VERSION ""

NS_ :

BS_:

BU_: DBW AKit Pacifica MPDM_Master MPDM_Requester HMI

BO_ 3221225472 VECTOR__INDEPENDENT_SIG_MSG: 0 Vector__XXX
 SG_ DBW_BrakeFault_Ch2 : 55|1@1+ (1,0) [0|1] "Bool" Vector__XXX
 SG_ DBW_BrakeFault_Ch1 : 54|1@1+ (1,0) [0|1] "Bool" Vector__XXX
 SG_ DBW_TransCurGear : 4|4@1+ (1,0) [0|15] "uint8" Vector__XXX

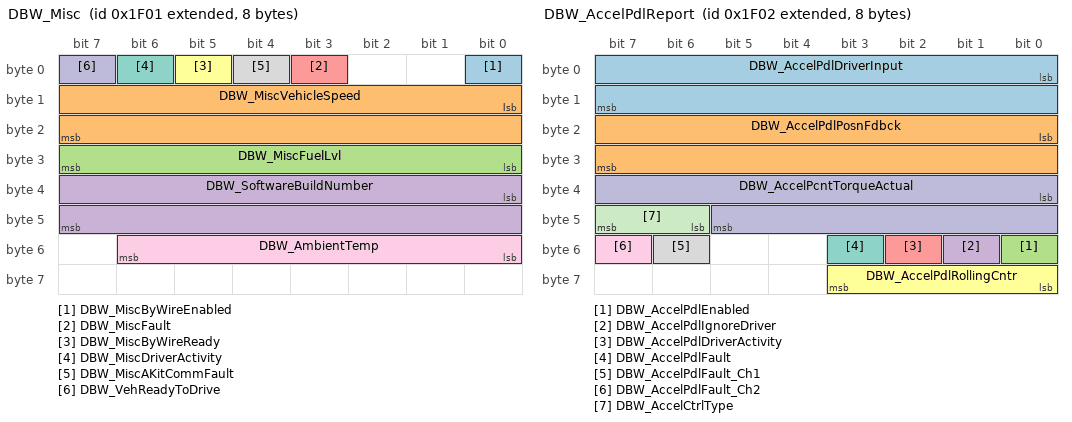
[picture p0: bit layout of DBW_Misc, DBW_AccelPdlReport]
BO_ 2147491585 DBW_Misc: 8 DBW
 SG_ DBW_MiscByWireEnabled : 0|1@1+ (1,0) [0|1] "Bool" Vector__XXX
 SG_ DBW_MiscVehicleSpeed : 8|16@1+ (0.00217014,0) [0|142.22] "m/s" Vector__XXX
 SG_ DBW_MiscFuelLvl : 24|8@1+ (0.5,0) [0|100] "%" Vector__XXX
 SG_ DBW_SoftwareBuildNumber : 32|16@1+ (1,0) [0|65535] "" Vector__XXX
 SG_ DBW_MiscFault : 3|1@1+ (1,0) [0|1] "Bool" Vector__XXX
 SG_ DBW_MiscByWireReady : 5|1@1+ (1,0) [0|1] "Bool" Vector__XXX
 SG_ DBW_MiscDriverActivity : 6|1@1+ (1,0) [0|1] "Bool" Vector__XXX
 SG_ DBW_MiscAKitCommFault : 4|1@1+ (1,0) [0|1] "Bool" Vector__XXX
 SG_ DBW_AmbientTemp : 48|7@1+ (1,-40) [-40|87] "C" Vector__XXX
 SG_ DBW_VehReadyToDrive : 7|1@1+ (1,0) [0|1] "Bool" Vector__XXX

BO_ 2147491586 DBW_AccelPdlReport: 8 DBW
 SG_ DBW_AccelPdlDriverInput : 0|16@1+ (0.1,0) [0|100] "%-pedal" Vector__XXX
 SG_ DBW_AccelPdlPosnFdbck : 16|16@1+ (0.1,0) [0|100] "%-pedal" Vector__XXX
 SG_ DBW_AccelPdlEnabled : 48|1@1+ (1,0) [0|1] "Bool" Vector__XXX
 SG_ DBW_AccelPdlIgnoreDriver : 49|1@1+ (1,0) [0|1] "Bool" Vector__XXX
 SG_ DBW_AccelPdlDriverActivity : 50|1@1+ (1,0) [0|1] "Bool" Vector__XXX
 SG_ DBW_AccelPdlRollingCntr : 56|4@1+ (1,0) [0|15] "" Vector__XXX
 SG_ DBW_AccelPdlFault : 51|1@1+ (1,0) [0|1] "Bool" Vector__XXX
 SG_ DBW_AccelPdlFault_Ch1 : 54|1@1+ (1,0) [0|1] "Bool" Vector__XXX
 SG_ DBW_AccelPdlFault_Ch2 : 55|1@1+ (1,0) [0|1] "Bool" Vector__XXX
 SG_ DBW_AccelPcntTorqueActual : 32|14@1+ (0.1,0) [0|100] "%-torque" Vector__XXX
 SG_ DBW_AccelCtrlType : 46|2@1+ (1,0) [0|3] "Enum" Vector__XXX

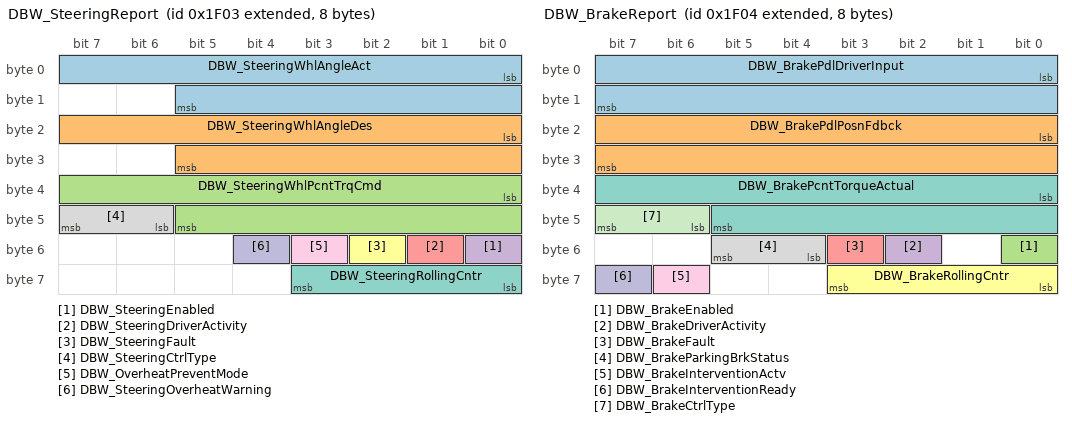
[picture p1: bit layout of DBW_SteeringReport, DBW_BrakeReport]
BO_ 2147491587 DBW_SteeringReport: 8 DBW
 SG_ DBW_SteeringWhlAngleAct : 0|14@1- (0.1,0) [-819.2|819.1] "deg" Vector__XXX
 SG_ DBW_SteeringWhlAngleDes : 16|14@1- (0.1,0) [-819.2|819.1] "deg" Vector__XXX
 SG_ DBW_SteeringWhlPcntTrqCmd : 32|14@1- (0.02,0) [-100|100] "%-torque" Vector__XXX
 SG_ DBW_SteeringEnabled : 48|1@1+ (1,0) [0|1] "Bool" Vector__XXX
 SG_ DBW_SteeringDriverActivity : 49|1@1+ (1,0) [0|1] "Bool" Vector__XXX
 SG_ DBW_SteeringFault : 50|1@1+ (1,0) [0|1] "Bool" Vector__XXX
 SG_ DBW_SteeringRollingCntr : 56|4@1+ (1,0) [0|15] "" Vector__XXX
 SG_ DBW_SteeringCtrlType : 46|2@1+ (1,0) [0|3] "Enum" Vector__XXX
 SG_ DBW_OverheatPreventMode : 51|1@1+ (1,0) [0|1] "Bool" Vector__XXX
 SG_ DBW_SteeringOverheatWarning : 52|1@1+ (1,0) [0|1] "Bool" Vector__XXX

BO_ 2147491588 DBW_BrakeReport: 8 DBW
 SG_ DBW_BrakePdlDriverInput : 0|16@1+ (0.1,0) [0|100] "%-pedal" Vector__XXX
 SG_ DBW_BrakePdlPosnFdbck : 16|16@1+ (0.1,0) [0|100] "%-pedal" Vector__XXX
 SG_ DBW_BrakeEnabled : 48|1@1+ (1,0) [0|1] "Bool" Vector__XXX
 SG_ DBW_BrakeDriverActivity : 50|1@1+ (1,0) [0|1] "Bool" Vector__XXX
 SG_ DBW_BrakeFault : 51|1@1+ (1,0) [0|1] "Bool" Vector__XXX
 SG_ DBW_BrakeRollingCntr : 56|4@1+ (1,0) [0|15] "" Vector__XXX
 SG_ DBW_BrakePcntTorqueActual : 32|14@1+ (0.1,0) [0|100] "%-torque" Vector__XXX
 SG_ DBW_BrakeParkingBrkStatus : 52|2@1+ (1,0) [0|3] "Enum" Vector__XXX
 SG_ DBW_BrakeInterventionActv : 62|1@1+ (1,0) [0|1] "Bool" Vector__XXX
 SG_ DBW_BrakeInterventionReady : 63|1@1+ (1,0) [0|1] "Bool" Vector__XXX
 SG_ DBW_BrakeCtrlType : 46|2@1+ (1,0) [0|3] "Enum" Vector__XXX

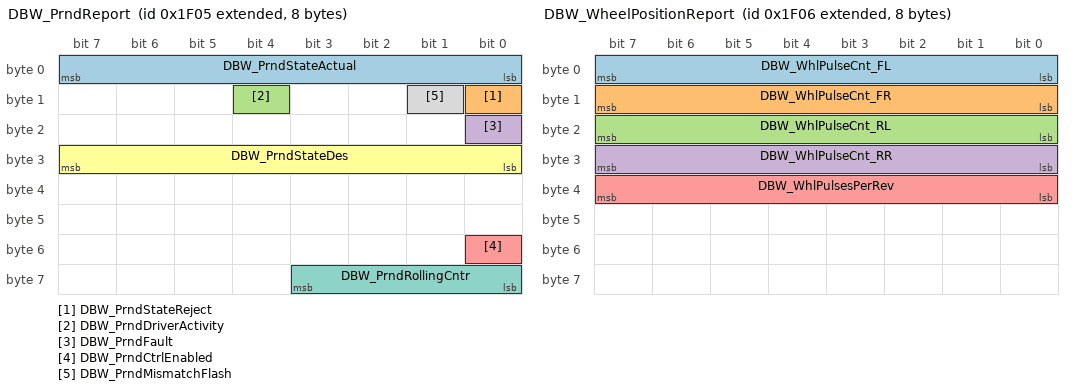
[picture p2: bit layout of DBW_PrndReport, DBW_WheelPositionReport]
BO_ 2147491589 DBW_PrndReport: 8 DBW
 SG_ DBW_PrndStateActual : 0|8@1+ (1,0) [0|255] "Enum" Vector__XXX
 SG_ DBW_PrndStateReject : 8|1@1+ (1,0) [0|1] "Bool" Vector__XXX
 SG_ DBW_PrndDriverActivity : 12|1@1+ (1,0) [0|1] "Bool" Vector__XXX
 SG_ DBW_PrndFault : 16|1@1+ (1,0) [0|1] "Bool" Vector__XXX
 SG_ DBW_PrndCtrlEnabled : 48|1@1+ (1,0) [0|1] "Bool" Vector__XXX
 SG_ DBW_PrndStateDes : 24|8@1+ (1,0) [0|255] "Enum" Vector__XXX
 SG_ DBW_PrndRollingCntr : 56|4@1+ (1,0) [0|15] "" Vector__XXX
 SG_ DBW_PrndMismatchFlash : 9|1@1+ (1,0) [0|1] "Bool" Vector__XXX

BO_ 2147491590 DBW_WheelPositionReport: 8 DBW
 SG_ DBW_WhlPulseCnt_FL : 0|8@1+ (1,0) [0|254] "Count" Vector__XXX
 SG_ DBW_WhlPulseCnt_FR : 8|8@1+ (1,0) [0|254] "Count" Vector__XXX
 SG_ DBW_WhlPulseCnt_RL : 16|8@1+ (1,0) [0|254] "Count" Vector__XXX
 SG_ DBW_WhlPulseCnt_RR : 24|8@1+ (1,0) [0|254] "Count" Vector__XXX
 SG_ DBW_WhlPulsesPerRev : 32|8@1+ (1,0) [0|255] "Count" Vector__XXX

BO_ 2147495682 AKit_AccelPdlRequest: 8 AKit
 SG_ AKit_AccelPdlReq m0 : 0|14@1+ (0.1,0) [0|100] "%-pedal" Vector__XXX
 SG_ AKit_AccelPdlEnblReq : 52|1@1+ (1,0) [0|1] "Bool" Vector__XXX
 SG_ AKit_AccelPdlIgnoreDriverOvrd : 53|1@1+ (1,0) [0|1] "Bool" Vector__XXX
 SG_ AKit_AccelPdlRollingCntr : 48|4@1+ (1,0) [0|15] "" Vector__XXX
 SG_ AKit_AccelReqType M : 40|3@0+ (1,0) [0|7] "Enum" Vector__XXX
 SG_ AKit_AccelPcntTorqueReq m1 : 0|14@1+ (0.1,0) [0|100] "%-torque" Vector__XXX
 SG_ AKit_SpeedReq m2 : 0|14@1+ (0.005,0) [0|81.915] "m/s" Vector__XXX
 SG_ AKit_SpeedModeRoadSlope m2 : 32|8@1- (0.2,0) [-25.5|25.5] "degrees" Vector__XXX
 SG_ AKit_AccelPdlChecksum : 56|8@1+ (1,0) [0|255] "" Vector__XXX
 SG_ AKit_SpeedModeAccelLim m2 : 16|8@1+ (0.1,0) [0|25.5] "m/s^2" Vector__XXX
 SG_ AKit_SpeedModePosJerkLim m2 : 24|8@1+ (0.1,0) [0|25.5] "m/s^3" Vector__XXX

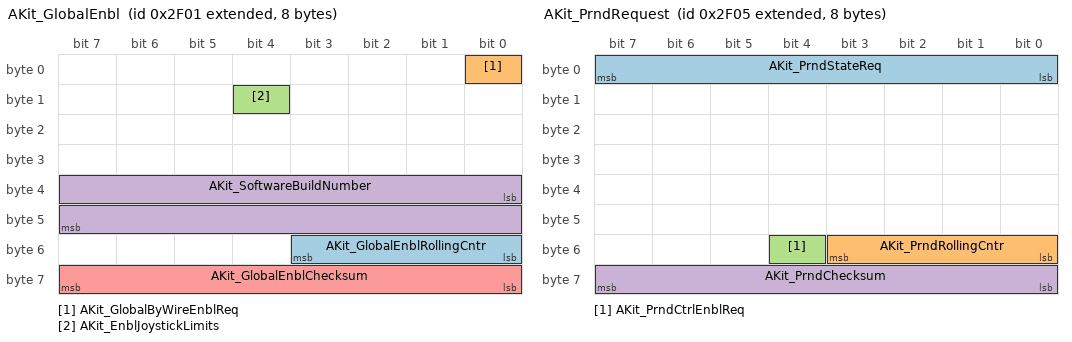
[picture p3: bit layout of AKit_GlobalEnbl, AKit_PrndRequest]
BO_ 2147495681 AKit_GlobalEnbl: 8 AKit
 SG_ AKit_GlobalEnblRollingCntr : 48|4@1+ (1,0) [0|15] "" Vector__XXX
 SG_ AKit_GlobalByWireEnblReq : 0|1@1+ (1,0) [0|1] "Bool" Vector__XXX
 SG_ AKit_EnblJoystickLimits : 12|1@1+ (1,0) [0|1] "Bool" Vector__XXX
 SG_ AKit_SoftwareBuildNumber : 32|16@1+ (1,0) [0|65535] "" Vector__XXX
 SG_ AKit_GlobalEnblChecksum : 56|8@1+ (1,0) [0|15] "" Vector__XXX

BO_ 2147495686 AKit_OtherActuators: 8 AKit
 SG_ AKit_TurnSignalReq : 4|2@1+ (1,0) [0|3] "Enum" Vector__XXX
 SG_ AKit_RightRearDoorReq : 8|2@1+ (1,0) [0|3] "Enum" Vector__XXX
 SG_ AKit_HighBeamReq : 28|2@1+ (1,0) [0|3] "" Vector__XXX
 SG_ AKit_FrontWiperReq : 16|4@1+ (1,0) [0|15] "Enum" Vector__XXX
 SG_ AKit_RearWiperReq : 20|4@1+ (1,0) [0|15] "Enum" Vector__XXX
 SG_ AKit_IgnitionReq : 24|3@1+ (1,0) [0|7] "Enum" Vector__XXX
 SG_ AKit_LeftRearDoorReq : 10|2@1+ (1,0) [0|3] "Enum" Vector__XXX
 SG_ AKit_LiftgateDoorReq : 32|2@1+ (1,0) [0|3] "Enum" Vector__XXX
 SG_ AKit_BlockBasicCruiseCtrlBtns : 13|1@1+ (1,0) [0|1] "" Vector__XXX
 SG_ AKit_BlockAdapCruiseCtrlBtns : 14|1@1+ (1,0) [0|1] "" Vector__XXX
 SG_ AKit_BlockTurnSigStalkInpts : 15|1@1+ (1,0) [0|1] "" Vector__XXX
 SG_ AKit_OtherRollingCntr : 48|4@1+ (1,0) [0|15] "" Vector__XXX
 SG_ AKit_OtherChecksum : 56|8@1+ (1,0) [0|255] "" Vector__XXX
 SG_ AKit_HornReq : 12|1@1+ (1,0) [0|1] "Bool" Vector__XXX
 SG_ AKit_LowBeamReq : 30|2@1+ (1,0) [0|2] "Enum" Vector__XXX
 SG_ AKit_DoorLockReq : 0|2@1+ (1,0) [0|2] "Enum" Vector__XXX
 SG_ AKit_RunningLightsReq : 34|3@1+ (1,0) [0|3] "Enum" Vector__XXX
 SG_ AKit_ModeLight_Red : 40|1@1+ (1,0) [0|1] "Bool" Vector__XXX
 SG_ AKit_ModeLight_Yellow : 41|1@1+ (1,0) [0|1] "Bool" Vector__XXX
 SG_ AKit_ModeLight_Green : 42|1@1+ (1,0) [0|1] "Bool" Vector__XXX
 SG_ AKit_ModeLight_Blue : 43|1@1+ (1,0) [0|1] "Bool" Vector__XXX
 SG_ AKit_DiffLock : 44|1@1+ (1,0) [0|1] "Bool" Vector__XXX
 SG_ AKit_OtherLightsReq : 46|2@1+ (1,0) [0|3] "Enum" Vector__XXX

BO_ 2147495683 AKit_SteeringRequest: 8 AKit
 SG_ AKit_SteeringWhlAngleReq m1 : 0|14@1- (0.1,0) [-819.2|819.1] "deg" Vector__XXX
 SG_ AKit_SteeringWhlAngleVelocityLim : 16|7@1+ (10,0) [0|1270] "deg/s" Vector__XXX
 SG_ AKit_SteerCtrlEnblReq : 52|1@1+ (1,0) [0|0] "" Vector__XXX
 SG_ AKit_SteerRollingCntr : 48|4@1+ (1,0) [0|15] "" Vector__XXX
 SG_ AKit_SteeringWhlIgnoreDriverOvrd : 53|1@1+ (1,0) [0|1] "" Vector__XXX
 SG_ AKit_SteeringWhlPcntTrqReq m0 : 0|14@1- (0.02,0) [-100|100] "%-torque" Vector__XXX
 SG_ AKit_SteeringReqType M : 40|3@0+ (1,0) [0|7] "Enum" Vector__XXX
 SG_ AKit_SteeringVehCurvatureReq m2 : 0|14@1- (0.0001,0) [-0.8192|0.8191] "1/m" Vector__XXX
 SG_ AKit_SteeringChecksum : 56|8@1+ (1,0) [0|255] "" Vector__XXX

BO_ 2147495684 AKit_BrakeRequest: 8 AKit
 SG_ AKit_BrakePedalReq m0 : 0|14@1+ (0.1,0) [0|100] "%-pedal" Vector__XXX
 SG_ AKit_BrakeRollingCntr : 48|4@1+ (1,0) [0|15] "" Vector__XXX
 SG_ AKit_BrakeCtrlEnblReq : 52|1@1+ (1,0) [0|1] "Bool" Vector__XXX
 SG_ AKit_BrakeCtrlReqType M : 40|3@0+ (1,0) [0|7] "Enum" Vector__XXX
 SG_ AKit_BrakePcntTorqueReq m1 : 0|14@1+ (0.1,0) [0|100] "%-torque" Vector__XXX
 SG_ AKit_SpeedModeDecelLim m2 : 16|8@1+ (0.1,0) [0|25.5] "m/s^2" Vector__XXX
 SG_ AKit_BrakeChecksum : 56|8@1+ (1,0) [0|255] "" Vector__XXX
 SG_ AKit_SpeedModeNegJerkLim m2 : 24|8@1+ (0.1,0) [0|25.5] "m/s^3" Vector__XXX
 SG_ AKit_ParkingBrkReq : 14|2@1+ (1,0) [0|2] "Enum" Vector__XXX

BO_ 2147495685 AKit_PrndRequest: 8 AKit
 SG_ AKit_PrndStateReq : 0|8@1+ (1,0) [0|255] "Enum" Vector__XXX
 SG_ AKit_PrndRollingCntr : 48|4@1+ (1,0) [0|15] "" Vector__XXX
 SG_ AKit_PrndCtrlEnblReq : 52|1@1+ (1,0) [0|1] "Bool" Vector__XXX
 SG_ AKit_PrndChecksum : 56|8@1+ (1,0) [0|255] "" Vector__XXX

BO_ 2147491599 DBW_DriverInputs: 8 DBW
 SG_ DBW_OccupAnyDoorOrHoodAjar : 0|1@1+ (1,0) [0|1] "Bool" Vector__XXX
 SG_ DBW_OccupAnyAirbagDeployed : 8|1@1+ (1,0) [0|1] "Bool" Vector__XXX
 SG_ DBW_OccupAnySeatbeltUnbuckled : 16|1@1+ (1,0) [0|1] "Bool" Vector__XXX
 SG_ DBW_DrvInptCruiseResumeBtn : 24|1@1+ (1,0) [0|1] "Bool" Vector__XXX
 SG_ DBW_DrvInptCruiseCancelBtn : 25|1@1+ (1,0) [0|1] "Bool" Vector__XXX
 SG_ DBW_DrvInptCruiseAccelBtn : 26|1@1+ (1,0) [0|1] "Bool" Vector__XXX
 SG_ DBW_DrvInptCruiseDecelBtn : 27|1@1+ (1,0) [0|1] "Bool" Vector__XXX
 SG_ DBW_DrvInptCruiseOnOffBtn : 28|1@1+ (1,0) [0|1] "Bool" Vector__XXX
 SG_ DBW_DrvInptAccOnOffBtn : 29|1@1+ (1,0) [0|1] "Bool" Vector__XXX
 SG_ DBW_DrvInptAccIncDistBtn : 30|1@1+ (1,0) [0|1] "Bool" Vector__XXX
 SG_ DBW_DrvInptAccDecDistBtn : 31|1@1+ (1,0) [0|1] "Bool" Vector__XXX
 SG_ DBW_DrvInptHiBeam : 32|2@1+ (1,0) [0|3] "enum" Vector__XXX
 SG_ DBW_DrvInptTurnSignal : 34|2@1+ (1,0) [0|3] "enum" Vector__XXX
 SG_ DBW_DrvInptWiper : 36|4@1+ (1,0) [0|15] "enum" Vector__XXX
 SG_ DBW_DrvInputStrWhlBtnA : 17|1@1+ (1,0) [0|0] "" Vector__XXX
 SG_ DBW_DrvInputStrWhlBtnB : 18|1@1+ (1,0) [0|0] "" Vector__XXX
 SG_ DBW_DrvInputStrWhlBtnC : 19|1@1+ (1,0) [0|0] "" Vector__XXX
 SG_ DBW_DrvInputStrWhlBtnD : 20|1@1+ (1,0) [0|0] "" Vector__XXX
 SG_ DBW_DrvInputStrWhlBtnE : 21|1@1+ (1,0) [0|0] "" Vector__XXX

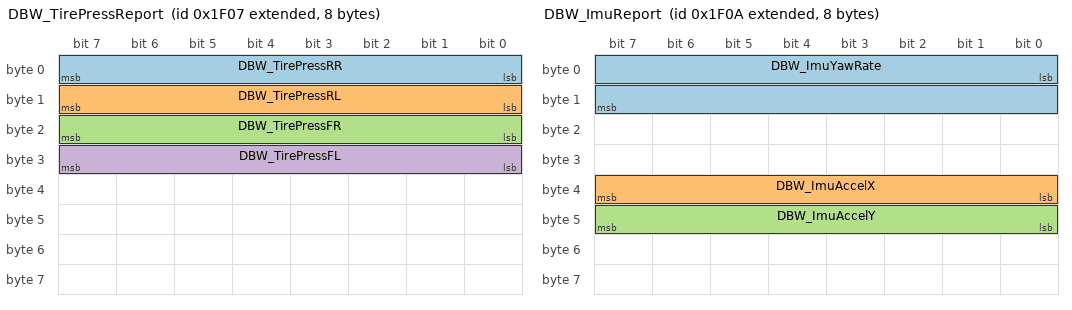
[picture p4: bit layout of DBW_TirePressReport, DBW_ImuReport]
BO_ 2147491591 DBW_TirePressReport: 8 DBW
 SG_ DBW_TirePressRR : 0|8@1+ (6.89476,0) [0|868.739] "kPa" Vector__XXX
 SG_ DBW_TirePressRL : 8|8@1+ (6.89476,0) [0|868.739] "kPa" Vector__XXX
 SG_ DBW_TirePressFR : 16|8@1+ (6.89476,0) [0|868.739] "kPa" Vector__XXX
 SG_ DBW_TirePressFL : 24|8@1+ (6.89476,0) [0|868.739] "kPa" Vector__XXX

BO_ 2147491592 DBW_VinReport: 8 DBW
 SG_ DBW_VinMultiplexor M : 0|2@1+ (1,0) [0|2] "" Vector__XXX
 SG_ DBW_VinDigit_01 m0 : 8|8@1+ (1,0) [30|90] "ascii" Vector__XXX
 SG_ DBW_VinDigit_02 m0 : 16|8@1+ (1,0) [30|90] "ascii" Vector__XXX
 SG_ DBW_VinDigit_03 m0 : 24|8@1+ (1,0) [30|90] "ascii" Vector__XXX
 SG_ DBW_VinDigit_04 m0 : 32|8@1+ (1,0) [30|90] "ascii" Vector__XXX
 SG_ DBW_VinDigit_05 m0 : 40|8@1+ (1,0) [30|90] "ascii" Vector__XXX
 SG_ DBW_VinDigit_06 m0 : 48|8@1+ (1,0) [30|90] "ascii" Vector__XXX
 SG_ DBW_VinDigit_07 m0 : 56|8@1+ (1,0) [30|90] "ascii" Vector__XXX
 SG_ DBW_VinDigit_08 m1 : 8|8@1+ (1,0) [30|90] "ascii" Vector__XXX
 SG_ DBW_VinDigit_09 m1 : 16|8@1+ (1,0) [30|90] "ascii" Vector__XXX
 SG_ DBW_VinDigit_10 m1 : 24|8@1+ (1,0) [30|90] "ascii" Vector__XXX
 SG_ DBW_VinDigit_11 m1 : 32|8@1+ (1,0) [30|90] "ascii" Vector__XXX
 SG_ DBW_VinDigit_12 m1 : 40|8@1+ (1,0) [30|90] "ascii" Vector__XXX
 SG_ DBW_VinDigit_13 m1 : 48|8@1+ (1,0) [30|90] "ascii" Vector__XXX
 SG_ DBW_VinDigit_14 m1 : 56|8@1+ (1,0) [30|90] "ascii" Vector__XXX
 SG_ DBW_VinDigit_15 m2 : 8|8@1+ (1,0) [30|90] "ascii" Vector__XXX
 SG_ DBW_VinDigit_16 m2 : 16|8@1+ (1,0) [30|90] "ascii" Vector__XXX
 SG_ DBW_VinDigit_17 m2 : 24|8@1+ (1,0) [30|90] "ascii" Vector__XXX

BO_ 2147491593 DBW_Reserved1: 8 DBW

BO_ 2147491594 DBW_ImuReport: 8 DBW
 SG_ DBW_ImuYawRate : 0|16@1+ (0.01,-327.68) [-327.68|327.66] "deg/sec" Vector__XXX
 SG_ DBW_ImuAccelX : 32|8@1+ (0.08,-10.24) [-10.24|10.08] "m/s/s" Vector__XXX
 SG_ DBW_ImuAccelY : 40|8@1+ (0.08,-10.24) [-10.24|10.08] "m/s/s" Vector__XXX

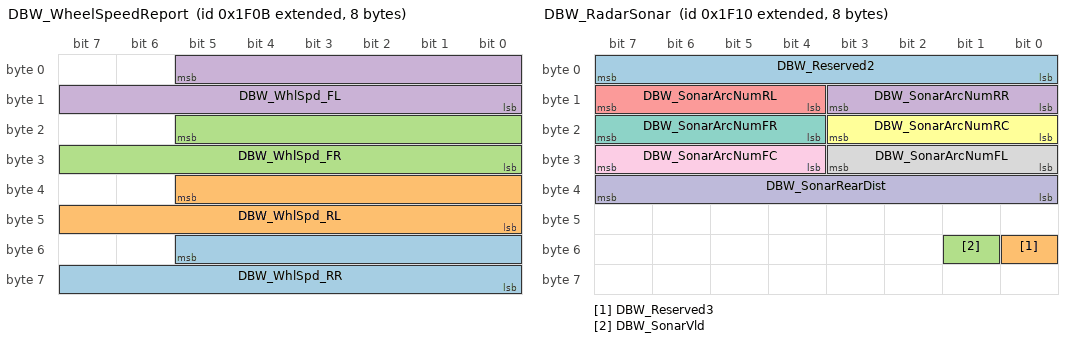
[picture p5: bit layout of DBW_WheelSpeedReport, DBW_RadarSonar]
BO_ 2147491595 DBW_WheelSpeedReport: 8 DBW
 SG_ DBW_WhlSpd_RR : 53|14@0- (0.0523599,0) [-428.932|428.827581] "rad/sec" Vector__XXX
 SG_ DBW_WhlSpd_RL : 37|14@0- (0.0523599,0) [-428.932|428.827581] "rad/sec" Vector__XXX
 SG_ DBW_WhlSpd_FR : 21|14@0- (0.0523599,0) [-428.932|428.827581] "rad/sec" Vector__XXX
 SG_ DBW_WhlSpd_FL : 5|14@0- (0.0523599,0) [-428.932|428.827581] "rad/sec" Vector__XXX

BO_ 2147491600 DBW_RadarSonar: 8 DBW
 SG_ DBW_Reserved2 : 0|8@1+ (1,0) [0|253] "m" Vector__XXX
 SG_ DBW_Reserved3 : 48|1@1+ (1,0) [0|1] "Bool" Vector__XXX
 SG_ DBW_SonarVld : 49|1@1+ (1,0) [0|1] "Bool" Vector__XXX
 SG_ DBW_SonarArcNumRR : 8|4@1+ (1,0) [0|15] "Enum" Vector__XXX
 SG_ DBW_SonarArcNumRL : 12|4@1+ (1,0) [0|15] "Enum" Vector__XXX
 SG_ DBW_SonarArcNumRC : 16|4@1+ (1,0) [0|15] "Enum" Vector__XXX
 SG_ DBW_SonarArcNumFR : 20|4@1+ (1,0) [0|15] "Enum" Vector__XXX
 SG_ DBW_SonarArcNumFL : 24|4@1+ (1,0) [0|15] "Enum" Vector__XXX
 SG_ DBW_SonarArcNumFC : 28|4@1+ (1,0) [0|15] "Enum" Vector__XXX
 SG_ DBW_SonarRearDist : 32|8@1+ (0.01,0) [0|2.54] "m" Vector__XXX

BO_ 1807 DBW_FaultText: 8 DBW
 SG_ FltTxt_PageNum M : 0|8@1+ (1,0) [0|255] "" Vector__XXX
 SG_ FltTxt_FaultId m0 : 15|16@0+ (1,0) [0|65535] "" Vector__XXX
 SG_ FltTxt_NumPages m0 : 40|8@1+ (1,0) [0|10] "" Vector__XXX
 SG_ FltTxt_FaultStatus m0 : 48|8@1+ (1,0) [0|2] "enum" Vector__XXX
 SG_ FltTxt_FaultSetRuntime m255 : 15|32@0+ (1,0) [0|0] "ms" Vector__XXX
 SG_ FltTxt_CRC m255 : 56|8@1+ (1,0) [0|255] "" Vector__XXX
 SG_ FltTxt_CurrentRuntime m254 : 39|32@0+ (1,0) [0|0] "ms" Vector__XXX
 SG_ FltTxt_Char01 m1 : 8|8@1+ (1,0) [0|255] "ascii" Vector__XXX
 SG_ FltTxt_Char02 m1 : 16|8@1+ (1,0) [0|255] "ascii" Vector__XXX
 SG_ FltTxt_Char03 m1 : 24|8@1+ (1,0) [0|255] "ascii" Vector__XXX
 SG_ FltTxt_Char04 m1 : 32|8@1+ (1,0) [0|255] "ascii" Vector__XXX
 SG_ FltTxt_Char05 m1 : 40|8@1+ (1,0) [0|255] "ascii" Vector__XXX
 SG_ FltTxt_Char06 m1 : 48|8@1+ (1,0) [0|255] "ascii" Vector__XXX
 SG_ FltTxt_Char07 m1 : 56|8@1+ (1,0) [0|255] "ascii" Vector__XXX
 SG_ FltTxt_Char08 m2 : 8|8@1+ (1,0) [0|255] "ascii" Vector__XXX
 SG_ FltTxt_Char09 m2 : 16|8@1+ (1,0) [0|255] "ascii" Vector__XXX
 SG_ FltTxt_Char10 m2 : 24|8@1+ (1,0) [0|255] "ascii" Vector__XXX
 SG_ FltTxt_Char11 m2 : 32|8@1+ (1,0) [0|255] "ascii" Vector__XXX
 SG_ FltTxt_Char12 m2 : 40|8@1+ (1,0) [0|255] "ascii" Vector__XXX
 SG_ FltTxt_Char13 m2 : 48|8@1+ (1,0) [0|255] "ascii" Vector__XXX
 SG_ FltTxt_Char14 m2 : 56|8@1+ (1,0) [0|255] "ascii" Vector__XXX
 SG_ FltTxt_Char15 m3 : 8|8@1+ (1,0) [0|255] "ascii" Vector__XXX
 SG_ FltTxt_Char16 m3 : 16|8@1+ (1,0) [0|255] "ascii" Vector__XXX
 SG_ FltTxt_Char17 m3 : 24|8@1+ (1,0) [0|255] "ascii" Vector__XXX
 SG_ FltTxt_Char18 m3 : 32|8@1+ (1,0) [0|255] "ascii" Vector__XXX
 SG_ FltTxt_Char19 m3 : 40|8@1+ (1,0) [0|255] "ascii" Vector__XXX
 SG_ FltTxt_Char20 m3 : 48|8@1+ (1,0) [0|255] "ascii" Vector__XXX
 SG_ FltTxt_Char21 m3 : 56|8@1+ (1,0) [0|255] "ascii" Vector__XXX
 SG_ FltTxt_Char22 m4 : 8|8@1+ (1,0) [0|255] "ascii" Vector__XXX
 SG_ FltTxt_Char23 m4 : 16|8@1+ (1,0) [0|255] "ascii" Vector__XXX
 SG_ FltTxt_Char24 m4 : 24|8@1+ (1,0) [0|255] "ascii" Vector__XXX
 SG_ FltTxt_Char25 m4 : 32|8@1+ (1,0) [0|255] "ascii" Vector__XXX
 SG_ FltTxt_Char26 m4 : 40|8@1+ (1,0) [0|255] "ascii" Vector__XXX
 SG_ FltTxt_Char27 m4 : 48|8@1+ (1,0) [0|255] "ascii" Vector__XXX
 SG_ FltTxt_Char28 m4 : 56|8@1+ (1,0) [0|255] "ascii" Vector__XXX
 SG_ FltTxt_Char29 m5 : 8|8@1+ (1,0) [0|255] "ascii" Vector__XXX
 SG_ FltTxt_Char30 m5 : 16|8@1+ (1,0) [0|255] "ascii" Vector__XXX
 SG_ FltTxt_Char31 m5 : 24|8@1+ (1,0) [0|255] "ascii" Vector__XXX
 SG_ FltTxt_Char32 m5 : 32|8@1+ (1,0) [0|255] "ascii" Vector__XXX
 SG_ FltTxt_Char33 m5 : 40|8@1+ (1,0) [0|255] "ascii" Vector__XXX
 SG_ FltTxt_Char34 m5 : 48|8@1+ (1,0) [0|255] "ascii" Vector__XXX
 SG_ FltTxt_Char35 m5 : 56|8@1+ (1,0) [0|255] "ascii" Vector__XXX
 SG_ FltTxt_Char36 m6 : 8|8@1+ (1,0) [0|255] "ascii" Vector__XXX
 SG_ FltTxt_Char37 m6 : 16|8@1+ (1,0) [0|255] "ascii" Vector__XXX
 SG_ FltTxt_Char38 m6 : 24|8@1+ (1,0) [0|255] "ascii" Vector__XXX
 SG_ FltTxt_Char39 m6 : 32|8@1+ (1,0) [0|255] "ascii" Vector__XXX
 SG_ FltTxt_Char40 m6 : 40|8@1+ (1,0) [0|255] "ascii" Vector__XXX
 SG_ FltTxt_Char41 m6 : 48|8@1+ (1,0) [0|255] "ascii" Vector__XXX
 SG_ FltTxt_Char42 m6 : 56|8@1+ (1,0) [0|255] "ascii" Vector__XXX
 SG_ FltTxt_Char43 m7 : 8|8@1+ (1,0) [0|255] "ascii" Vector__XXX
 SG_ FltTxt_Char44 m7 : 16|8@1+ (1,0) [0|255] "ascii" Vector__XXX
 SG_ FltTxt_Char45 m7 : 24|8@1+ (1,0) [0|255] "ascii" Vector__XXX
 SG_ FltTxt_Char46 m7 : 32|8@1+ (1,0) [0|255] "ascii" Vector__XXX
 SG_ FltTxt_Char47 m7 : 40|8@1+ (1,0) [0|255] "ascii" Vector__XXX
 SG_ FltTxt_Char48 m7 : 48|8@1+ (1,0) [0|255] "ascii" Vector__XXX
 SG_ FltTxt_Char49 m7 : 56|8@1+ (1,0) [0|255] "ascii" Vector__XXX

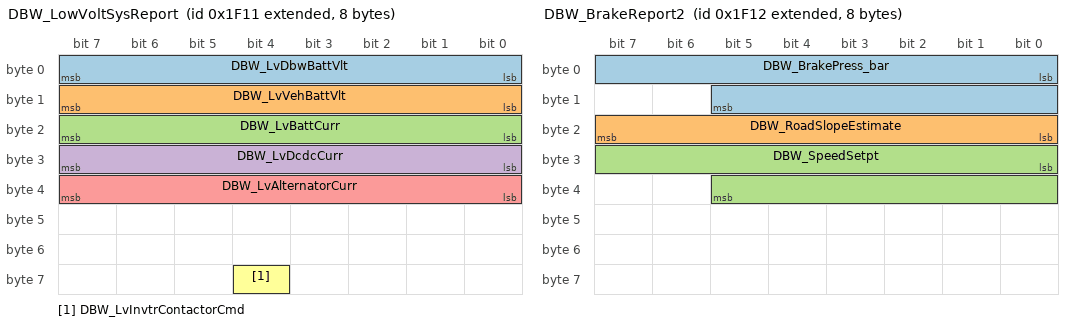
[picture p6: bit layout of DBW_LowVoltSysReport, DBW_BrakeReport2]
BO_ 2147491601 DBW_LowVoltSysReport: 8 DBW
 SG_ DBW_LvDbwBattVlt : 0|8@1+ (0.1,0) [0|25.5] "V" Vector__XXX
 SG_ DBW_LvVehBattVlt : 8|8@1+ (0.1,0) [0|25.5] "V" Vector__XXX
 SG_ DBW_LvBattCurr : 16|8@1+ (2,-256) [-256|254] "A" Vector__XXX
 SG_ DBW_LvDcdcCurr : 24|8@1+ (2,-256) [-256|254] "A" Vector__XXX
 SG_ DBW_LvAlternatorCurr : 32|8@1+ (2,-256) [-256|254] "A" Vector__XXX
 SG_ DBW_LvInvtrContactorCmd : 60|1@1+ (1,0) [0|1] "Bool" Vector__XXX

BO_ 2147491602 DBW_BrakeReport2: 8 DBW
 SG_ DBW_BrakePress_bar : 0|14@1+ (0.02,0) [0|200] "bar_gauge" Vector__XXX
 SG_ DBW_RoadSlopeEstimate : 16|8@1- (0.2,0) [-25.5|25.5] "degrees" Vector__XXX
 SG_ DBW_SpeedSetpt : 24|14@1+ (0.005,0) [0|81.915] "m/s" Vector__XXX

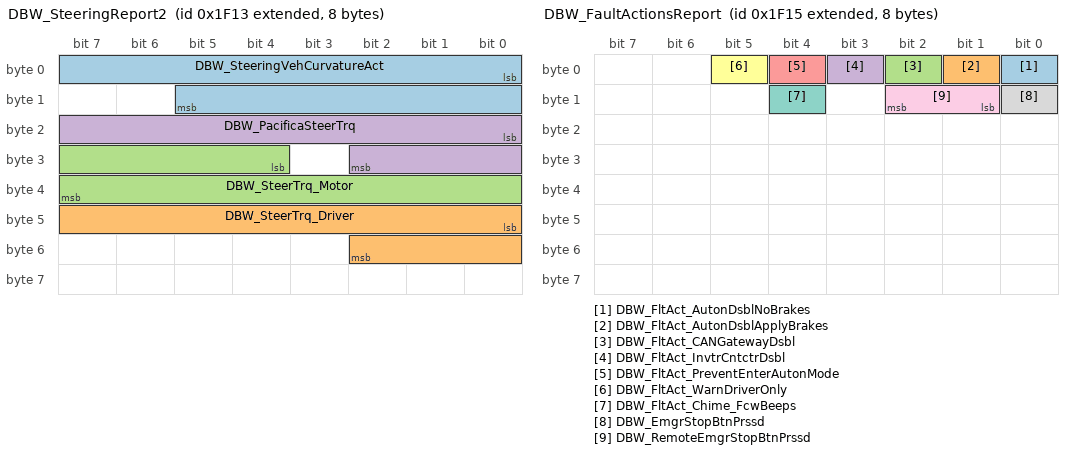
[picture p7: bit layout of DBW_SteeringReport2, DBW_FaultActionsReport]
BO_ 2147491603 DBW_SteeringReport2: 8 DBW
 SG_ DBW_SteeringVehCurvatureAct : 0|14@1- (0.0001,0) [-0.8192|0.8192] "1/m" Vector__XXX
 SG_ DBW_SteerTrq_Driver : 40|11@1- (0.1,0) [-100|100] "%-Torque" Vector__XXX
 SG_ DBW_SteerTrq_Motor : 28|12@1- (0.05,0) [-100|100] "%-Torque" Vector__XXX
 SG_ DBW_PacificaSteerTrq : 16|11@1+ (0.0078125,-8) [-8|7.99219] "Nm" Vector__XXX

BO_ 2147491604 DBW_OtherActuatorsReport: 8 DBW
 SG_ DBW_TurnSignalState : 4|3@1+ (1,0) [0|7] "Enum" Vector__XXX
 SG_ DBW_RightRearDoorState : 8|2@1+ (1,0) [0|3] "Enum" Vector__XXX
 SG_ DBW_HighBeamState : 28|2@1+ (1,0) [0|3] "Enum" Vector__XXX
 SG_ DBW_FrontWiperState : 16|4@1+ (1,0) [0|15] "Enum" Vector__XXX
 SG_ DBW_RearWiperState : 20|4@1+ (1,0) [0|15] "Enum" Vector__XXX
 SG_ DBW_IgnitionState : 24|3@1+ (1,0) [0|7] "Enum" Vector__XXX
 SG_ DBW_LeftRearDoorState : 10|2@1+ (1,0) [0|3] "Enum" Vector__XXX
 SG_ DBW_LiftgateDoorState : 32|2@1+ (1,0) [0|3] "Enum" Vector__XXX
 SG_ DBW_HornState : 12|2@1+ (1,0) [0|3] "Enum" Vector__XXX
 SG_ DBW_LowBeamState : 30|2@1+ (1,0) [0|3] "Enum" Vector__XXX
 SG_ DBW_OtherActRollingCntr : 56|4@1+ (1,0) [0|15] "" Vector__XXX
 SG_ DBW_DoorLockState : 0|2@1+ (1,0) [0|3] "Enum" Vector__XXX
 SG_ DBW_RunningLightsState : 34|2@1+ (1,0) [0|3] "Enum" Vector__XXX
 SG_ DBW_ModeLightState_Red : 40|2@1+ (1,0) [0|3] "Enum" Vector__XXX
 SG_ DBW_ModeLightState_Yellow : 42|2@1+ (1,0) [0|3] "Enum" Vector__XXX
 SG_ DBW_ModeLightState_Green : 48|2@1+ (1,0) [0|3] "Enum" Vector__XXX
 SG_ DBW_ModeLightState_Blue : 50|2@1+ (1,0) [0|3] "Enum" Vector__XXX
 SG_ DBW_DiffLockState : 44|2@1+ (1,0) [0|3] "Enum" Vector__XXX
 SG_ DBW_OtherLightsState : 46|2@1+ (1,0) [0|3] "Enum" Vector__XXX

BO_ 2147491605 DBW_FaultActionsReport: 8 DBW
 SG_ DBW_FltAct_AutonDsblNoBrakes : 0|1@1+ (1,0) [0|1] "" Vector__XXX
 SG_ DBW_FltAct_AutonDsblApplyBrakes : 1|1@1+ (1,0) [0|1] "" Vector__XXX
 SG_ DBW_FltAct_CANGatewayDsbl : 2|1@1+ (1,0) [0|1] "" Vector__XXX
 SG_ DBW_FltAct_InvtrCntctrDsbl : 3|1@1+ (1,0) [0|1] "" Vector__XXX
 SG_ DBW_FltAct_PreventEnterAutonMode : 4|1@1+ (1,0) [0|1] "" Vector__XXX
 SG_ DBW_FltAct_WarnDriverOnly : 5|1@1+ (1,0) [0|1] "" Vector__XXX
 SG_ DBW_FltAct_Chime_FcwBeeps : 12|1@1+ (1,0) [0|1] "" Vector__XXX
 SG_ DBW_EmgrStopBtnPrssd : 8|1@1+ (1,0) [0|1] "Bool" Vector__XXX
 SG_ DBW_RemoteEmgrStopBtnPrssd : 9|2@1+ (1,0) [0|3] "Enum" Vector__XXX

BO_ 2147491606 DBW_GpsReference: 8 DBW
 SG_ DBW_GpsRefLat : 0|16@1- (0.005,0) [-90|-90] "deg" Vector__XXX
 SG_ DBW_GpsRefLong : 16|16@1- (0.005,0) [-180|-180] "deg" Vector__XXX

BO_ 2147491607 DBW_GpsRemainder: 8 DBW
 SG_ DBW_GpsRemainderLat : 0|24@1- (0.001,0) [-8388.607|8388.608] "m" Vector__XXX
 SG_ DBW_GpsRemainderLong : 32|24@1- (0.001,0) [-8388.607|8388.61] "m" Vector__XXX

BO_ 2147495687 AKit_DumpBedRequest: 8 AKit
 SG_ AKit_DumpBedRollingCntr : 48|4@1+ (1,0) [0|15] "" Vector__XXX
 SG_ AKit_DumpBedChecksum : 56|8@1+ (1,0) [0|255] "" Vector__XXX
 SG_ AKit_DumpBedCtrlEnblReq : 52|1@1+ (1,0) [0|1] "" Vector__XXX
 SG_ AKit_DumpBedReqType M : 40|3@0+ (1,0) [0|1] "" Vector__XXX
 SG_ AKit_DumpBedModeReq m0 : 0|4@1+ (1,0) [0|5] "enum" Vector__XXX
 SG_ AKit_DumpBedLeverPercentReq m0 : 8|8@1+ (1,0) [0|100] "%" Vector__XXX
 SG_ AKit_DumpBedAnglReq m1 : 8|8@1+ (1,0) [0|100] "deg" Vector__XXX
 SG_ AKit_DumpBedIgnoreDriverOrvd : 53|1@1+ (1,0) [0|1] "" Vector__XXX
 SG_ AKit_DumpBedVelocityLimit : 16|8@1+ (0.5,0) [0|127.5] "deg/s" Vector__XXX

BO_ 2147495689 AKit_ArticulationRequest: 8 AKit
 SG_ AKit_ArticulationRollingCntr : 48|4@1+ (1,0) [0|15] "" Vector__XXX
 SG_ AKit_ArticulationChecksum : 56|8@1+ (1,0) [0|255] "" Vector__XXX
 SG_ AKit_ArticulationCtrlEnblReq : 52|1@1+ (1,0) [0|1] "" Vector__XXX
 SG_ AKit_ArticulationReqType M : 40|3@0+ (1,0) [0|1] "Enum" Vector__XXX
 SG_ AKit_ArticulationAngleReq m1 : 0|14@1- (0.1,0) [-90|90] "deg" Vector__XXX
 SG_ AKit_ArticulationIgnoreDrvrOvrd : 53|1@1+ (1,0) [0|1] "" Vector__XXX
 SG_ AKit_ArticulationVelocityLimit : 16|8@1+ (0.5,0) [0|127.5] "deg/s" Vector__XXX

BO_ 2147495688 AKit_EngineRequest: 8 AKit
 SG_ AKit_EngineCtrlEnblReq : 52|1@1+ (1,0) [0|1] "" Vector__XXX
 SG_ AKit_EngineRollingCntr : 48|4@1+ (1,0) [0|15] "" Vector__XXX
 SG_ AKit_EngineChecksum : 56|8@1+ (1,0) [0|255] "" Vector__XXX
 SG_ AKit_EngineModeReq m0 : 0|4@1+ (1,0) [0|4] "" Vector__XXX
 SG_ AKit_EngineReqType M : 40|3@0+ (1,0) [0|1] "" Vector__XXX

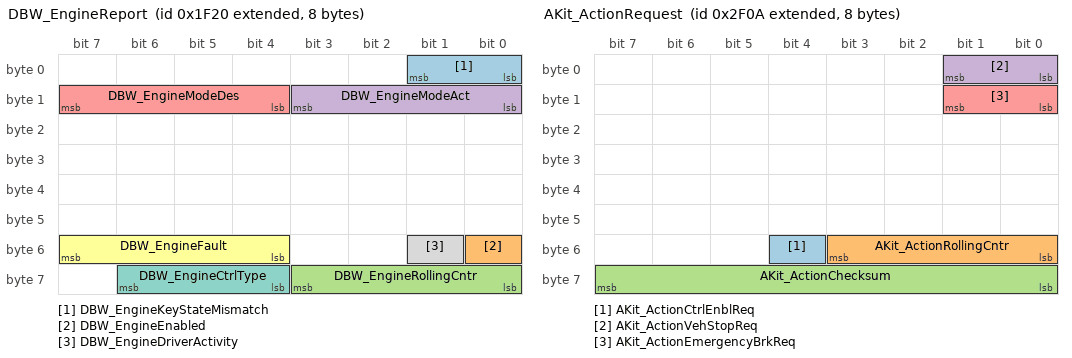
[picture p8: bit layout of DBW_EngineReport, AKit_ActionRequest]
BO_ 2147491616 DBW_EngineReport: 8 DBW
 SG_ DBW_EngineKeyStateMismatch : 0|2@1+ (1,0) [0|3] "enum" Vector__XXX
 SG_ DBW_EngineEnabled : 48|1@1+ (1,0) [0|1] "" Vector__XXX
 SG_ DBW_EngineRollingCntr : 56|4@1+ (1,0) [0|15] "" Vector__XXX
 SG_ DBW_EngineModeAct : 8|4@1+ (1,0) [0|4] "" Vector__XXX
 SG_ DBW_EngineModeDes : 12|4@1+ (1,0) [0|4] "" Vector__XXX
 SG_ DBW_EngineFault : 52|4@1+ (1,0) [0|15] "" Vector__XXX
 SG_ DBW_EngineCtrlType : 60|3@1+ (1,0) [0|1] "" Vector__XXX
 SG_ DBW_EngineDriverActivity : 49|1@1+ (1,0) [0|1] "" Vector__XXX

BO_ 2147495690 AKit_ActionRequest: 8 AKit
 SG_ AKit_ActionCtrlEnblReq : 52|1@1+ (1,0) [0|1] "" Vector__XXX
 SG_ AKit_ActionRollingCntr : 48|4@1+ (1,0) [0|15] "" Vector__XXX
 SG_ AKit_ActionChecksum : 56|8@1+ (1,0) [0|255] "" Vector__XXX
 SG_ AKit_ActionVehStopReq : 0|2@1+ (1,0) [0|3] "" Vector__XXX
 SG_ AKit_ActionEmergencyBrkReq : 8|2@1+ (1,0) [0|3] "" Vector__XXX

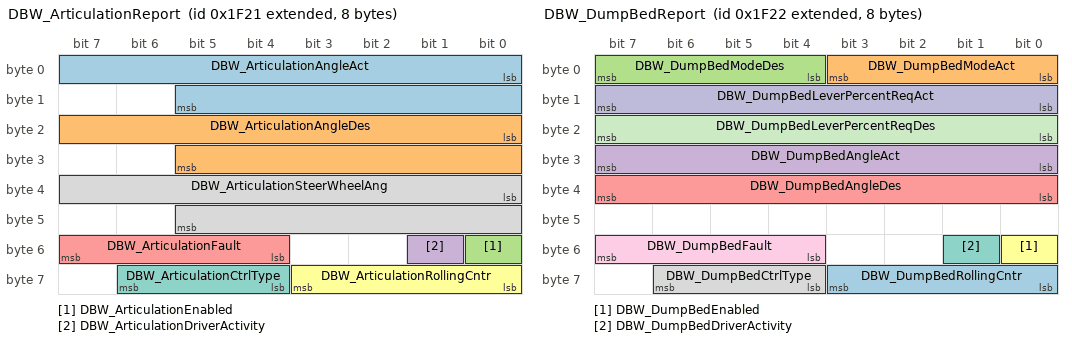
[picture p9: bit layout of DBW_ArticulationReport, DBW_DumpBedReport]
BO_ 2147491617 DBW_ArticulationReport: 8 DBW
 SG_ DBW_ArticulationAngleAct : 0|14@1- (0.1,0) [-90|90] "deg" Vector__XXX
 SG_ DBW_ArticulationAngleDes : 16|14@1- (0.1,0) [-90|90] "deg" Vector__XXX
 SG_ DBW_ArticulationEnabled : 48|1@1+ (1,0) [0|1] "" Vector__XXX
 SG_ DBW_ArticulationDriverActivity : 49|1@1+ (1,0) [0|1] "" Vector__XXX
 SG_ DBW_ArticulationFault : 52|4@1+ (1,0) [0|15] "" Vector__XXX
 SG_ DBW_ArticulationRollingCntr : 56|4@1+ (1,0) [0|15] "" Vector__XXX
 SG_ DBW_ArticulationCtrlType : 60|3@1+ (1,0) [0|1] "" Vector__XXX
 SG_ DBW_ArticulationSteerWheelAng : 32|14@1- (0.1,0) [-819.2|819.1] "deg" Vector__XXX

BO_ 2147491618 DBW_DumpBedReport: 8 DBW
 SG_ DBW_DumpBedRollingCntr : 56|4@1+ (1,0) [0|15] "" Vector__XXX
 SG_ DBW_DumpBedModeAct : 0|4@1+ (1,0) [0|5] "enum" Vector__XXX
 SG_ DBW_DumpBedModeDes : 4|4@1+ (1,0) [0|5] "enum" Vector__XXX
 SG_ DBW_DumpBedAngleAct : 24|8@1+ (1,0) [0|100] "deg" Vector__XXX
 SG_ DBW_DumpBedAngleDes : 32|8@1+ (1,0) [0|100] "deg" Vector__XXX
 SG_ DBW_DumpBedEnabled : 48|1@1+ (1,0) [0|1] "" Vector__XXX
 SG_ DBW_DumpBedDriverActivity : 49|1@1+ (1,0) [0|1] "" Vector__XXX
 SG_ DBW_DumpBedCtrlType : 60|3@1+ (1,0) [0|1] "" Vector__XXX
 SG_ DBW_DumpBedFault : 52|4@1+ (1,0) [0|1] "" Vector__XXX
 SG_ DBW_DumpBedLeverPercentReqAct : 8|8@1+ (1,0) [0|100] "%" Vector__XXX
 SG_ DBW_DumpBedLeverPercentReqDes : 16|8@1+ (1,0) [0|100] "%" Vector__XXX

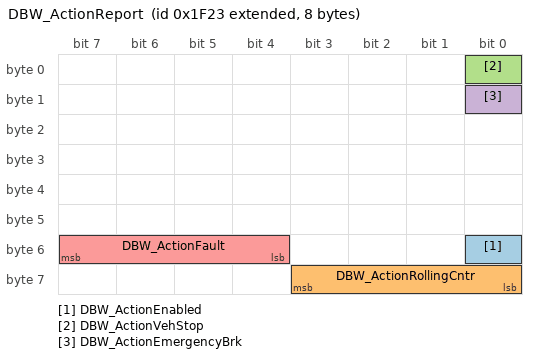
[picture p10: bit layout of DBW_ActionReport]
BO_ 2147491619 DBW_ActionReport: 8 DBW
 SG_ DBW_ActionEnabled : 48|1@1+ (1,0) [0|1] "" Vector__XXX
 SG_ DBW_ActionRollingCntr : 56|4@1+ (1,0) [0|15] "" Vector__XXX
 SG_ DBW_ActionVehStop : 0|1@1+ (1,0) [0|1] "" Vector__XXX
 SG_ DBW_ActionEmergencyBrk : 8|1@1+ (1,0) [0|1] "" Vector__XXX
 SG_ DBW_ActionFault : 52|4@1+ (1,0) [0|15] "" Vector__XXX

BO_ 2147491620 DBW_DumpBedReport2: 8 DBW
 SG_ DBW_Payload : 0|16@1+ (0.1,0) [0|6535.5] "metric ton" Vector__XXX
 SG_ DBW_DumpBed2RllngCntr : 56|4@1+ (1,0) [0|15] "" Vector__XXX

CM_ BU_ Pacifica "Just added a custom VIN-read message from this module";
CM_ BU_ MPDM_Master "Whichever module directly controls MPDM would be the MPDM Master (broadcasts status to other modules)";
CM_ BU_ MPDM_Requester "Any module that doesn't directly control the MPDM but might want to request a state would be an MPDM_Requester";
CM_ SG_ 3221225472 DBW_BrakeFault_Ch2 "VCU has detected hardware fault on brake sig 2


ROS Attribute: fault_ch2
";
CM_ SG_ 3221225472 DBW_BrakeFault_Ch1 "VCU has detected hardware fault on brake sig 1


ROS Attribute: fault_ch1
";
CM_ SG_ 3221225472 DBW_TransCurGear "Numeric gear number for step-gear (non hybrid) transmissions. This signal is just to allow the AKit to perform autostick (pseudo-manual) gear selection. 0 could be Park or Neutral. 1 could be Drive or Reverse. See DBW_PrndStateActual for P-R-N-D info.

For eCVT hybrids or single-speed EVs, this will only ever be 0 or 1.";
CM_ BO_ 2147491585 "ROS Topic: /raptor_dbw_interface/misc_report";
CM_ SG_ 2147491585 DBW_MiscByWireEnabled "Actual mode of the Drive-By-Wire system. THis is NOT read by the ROS system, it's only here so its in CAN logs for debugging purposes


ROS Attribute: drive_by_wire_enabled
";
CM_ SG_ 2147491585 DBW_MiscVehicleSpeed "scaled to match Pacifica's vehicle speed message


ROS Attribute: vehicle_speed
";
CM_ SG_ 2147491585 DBW_MiscFuelLvl "DBW will have to read IC_A1:AvgFuelLvl (liters) from the Pacifica and divide it by VehCfg3:VC_FUEL_CAP


ROS Attribute: fuel_level
";
CM_ SG_ 2147491585 DBW_SoftwareBuildNumber "Build number of the software that is currently flashed on the DBW control module


ROS Attribute: software_build_number
";
CM_ SG_ 2147491585 DBW_MiscFault "indicates one of the DBW actuators has faulted out. See individual report messages for more details.


ROS Attribute: general_actuator_fault
";
CM_ SG_ 2147491585 DBW_MiscByWireReady "Indicates the DBW is ready (vehicle running and not faulted) to enable if the AKit chooses to send an enable request. Driver overrides are not an input to this flag, so in some cases this flag will be true but by-wire control still might not be enabled.


ROS Attribute: by_wire_ready
";
CM_ SG_ 2147491585 DBW_MiscDriverActivity "Indicates the DBW has detected a driver overriding one of the actuators. This will disable by-wire operation until the enable request for the offending actuator is reset to zero. Note: Driver overrides will not clear the \"DBW_MiscByWireReady\" flag.


ROS Attribute: general_driver_activity
";
CM_ SG_ 2147491585 DBW_MiscAKitCommFault "Sets in conjunction with DBW_MiscFault IFF the DBW fault is related to losing communication with the autonomous system. This may have different fault actions than other faults in the DBW system.
Note: when this sets, the most often reason is because the AKit is not sending all 5 of the AKit* command messages. All 5 must be send, even if some of the enable requests are false.


ROS Attribute: comms_fault
";
CM_ SG_ 2147491585 DBW_AmbientTemp "Ambient (outside) temperature.

ROS Attribute:";
CM_ SG_ 2147491585 DBW_VehReadyToDrive "Indicates vehicle is ready to drive. For combustion-engine vehicles, it means the engine is started. For hybrids and electric vehicles, the engine may not be running but it means the driver has properly started the vehicle by pressing the ignition & brakes as needed.

This bit is NOT true if the vehicle is just in an ignition-on-engine-off state";
CM_ BO_ 2147491586 "ROS Topic: /raptor_dbw_interface/accelerator_pedal_report";
CM_ SG_ 2147491586 DBW_AccelPdlDriverInput "
ROS Attribute: pedal_input
";
CM_ SG_ 2147491586 DBW_AccelPdlPosnFdbck "Feedback from the Vehicle's Engine or Hybrid Control Module. 
For J1939 vehicles with TSC1 control (Volvo), this is a %-of-reference-torque.
For all other vehicles with physical pedal wiring intercepts (Pacifica), this is a %-of-pedal-position


ROS Attribute: pedal_output
";
CM_ SG_ 2147491586 DBW_AccelPdlEnabled "
ROS Attribute: enabled
";
CM_ SG_ 2147491586 DBW_AccelPdlIgnoreDriver "indicates the DBW system was requested by the AKit to ignore the driver's input.


ROS Attribute: ignore_driver
";
CM_ SG_ 2147491586 DBW_AccelPdlDriverActivity "Driver is pressing the accel pedal, which will switch the DBW system to manual mode unless the AKit is sending the AccelPdlIgnoreDriver flag. This flag latches and will unlatch when AKit_AccelPdlCtrlEnblCmd goes back to false.


ROS Attribute: driver_activity
";
CM_ SG_ 2147491586 DBW_AccelPdlRollingCntr "Watchdog alive rolling counter


ROS Attribute: rolling_counter
";
CM_ SG_ 2147491586 DBW_AccelPdlFault "AccelPdl system has a fault, either from the vehicle itself or from an error in the request message from the AKit


ROS Attribute: fault_accel_pedal_system
";
CM_ SG_ 2147491586 DBW_AccelPdlFault_Ch1 "VCU has detected hardware fault on accel pedal sig 1


ROS Attribute: fault_ch1
";
CM_ SG_ 2147491586 DBW_AccelPdlFault_Ch2 "VCU has detected hardware fault on accel pedal sig 2


ROS Attribute: fault_ch2
";
CM_ SG_ 2147491586 DBW_AccelPcntTorqueActual "This value is in % of a fixed reference value. This reference value depends only on the type of vehicle. Contact New Eagle to determine the reference value for your vehicle make/model.

100% reference values for each vehicle platform:
Chrylser Pacifica: 100% = 9.8 m/s^2 acceleration on flat ground at curb weight.
Volvo VNR:\t  100% = 9.8 m/s^2 acceleration on flat ground at curb weight.
Toyota Prius:\t  100% = 6.0 m/s^2 acceleration on flat ground at curb weight.

ROS Attribute: torque_actual
";
CM_ SG_ 2147491586 DBW_AccelCtrlType "Indicates whether the DBW kit is set to apply an open loop command (AKit responsible for performing all PID control),
 or requesting the DBW to apply PID control at the actuator level (turn wheel to a certain angle, or apply a certain amount of accel/brake torque & let AKit perform PID control on vehicle curvature/speed)
or requesting the DBW to perform all PID control at the vehicle level (control to a vehicle curvature and speed). If ReqType is 2, the requested speed will be taken from the signal AKit_SpeedReq in the AKit_AccelRequest message.
Some vehicles may not support all types!


ROS Attribute: control_type
";
CM_ BO_ 2147491587 "ROS Topic: /raptor_dbw_interface/steering_report";
CM_ SG_ 2147491587 DBW_SteeringWhlAngleAct "Actual position of the steering wheel. counterclockwise = positive


ROS Attribute: steering_wheel_angle
";
CM_ SG_ 2147491587 DBW_SteeringWhlAngleDes "Position that the DBW is trying to acheive. counterclockwise = positive


ROS Attribute: steering_wheel_angle_cmd
";
CM_ SG_ 2147491587 DBW_SteeringWhlPcntTrqCmd "Torque requested by the DBW to acheive the desired position. counterclockwise = positive

100% reference values for each vehicle platform:
Chrylser Pacifica: 100% = 105 Nm
Volvo VNR:\t  100% = 40 Nm
Toyota Prius:\t  not applicable, torque mode not supported

ROS Attribute: steering_wheel_torque
";
CM_ SG_ 2147491587 DBW_SteeringEnabled "
ROS Attribute: enabled
";
CM_ SG_ 2147491587 DBW_SteeringDriverActivity "Driver is turning the steering wheel, which will switch the DBW system to Manual mode. This flag latches and will unlatch when AKit_SteerCtrlEnblCmd goes back to false.


ROS Attribute: driver_activity
";
CM_ SG_ 2147491587 DBW_SteeringFault "Brake system has a fault, either from the vehicle itself or from an error in the request message from the AKit


ROS Attribute: fault_steering_system
";
CM_ SG_ 2147491587 DBW_SteeringRollingCntr "
ROS Attribute: rolling_counter
";
CM_ SG_ 2147491587 DBW_SteeringCtrlType "Indicates whether the DBW kit is set to apply an open loop command (AKit responsible for performing all PID control),
 or requesting the DBW to apply PID control at the actuator level (turn wheel to a certain angle, or apply a certain amount of accel/brake torque & let AKit perform PID control on vehicle curvature/speed)
or requesting the DBW to perform all PID control at the vehicle level (control to a vehicle curvature and speed). If ReqType is 2, the requested speed will be taken from the signal AKit_SpeedReq in the AKit_AccelRequest message.
Some vehicles may not support all types!


ROS Attribute: control_type
";
CM_ SG_ 2147491587 DBW_OverheatPreventMode "If the tires are rolling, the steady-state steering torque is relatively low compared to the not-moving case. If the vehicle speed is zero (tires arent rolling) then holding a constant steering angle requires the EPS motor to fight the spring force of the rubber on the pavement. In addition, the EPS system will have to apply this high torque continuously to prevent the steering wheel from springing back to the same angle as the rubber on the pavement. This high-torque for an extended period of time is not something the EPS system would encounter with a human driver because a human would release the steering wheel at 0mph. 

To better replicate the behavior of a human driver in this situation, if the vehicle speed is zero and the AKit steering request has not changed for more than 10 seconds then the DBW will set this flag to indicate that it has zeroed out the steering torque request (though autonomous control may still be enabled). As soon as the AKit steering request changes by a si";
CM_ SG_ 2147491587 DBW_SteeringOverheatWarning "This flag indicates the power steering motor is getting hot due to recent maneuvers commanded by the autonomous system (most likely lots of steering maneuvers at zero vehicle speed). Autonomous control and full steering torque will be allowed for some time, but eventually the power steering motor will derate itself. If this flag sets, the autonomous system needs to stop commanding the steering wheel to turn while at 0mph vehicle speed.";
CM_ BO_ 2147491588 "ROS Topic: /raptor_dbw_interface/Brake_report";
CM_ SG_ 2147491588 DBW_BrakePdlDriverInput "Position of actual driver requested brake pedal


ROS Attribute: pedal_position
";
CM_ SG_ 2147491588 DBW_BrakePdlPosnFdbck "Brake pedal command sent to vehicle


ROS Attribute: pedal_output
";
CM_ SG_ 2147491588 DBW_BrakeEnabled "Brake control enabled


ROS Attribute: enabled
";
CM_ SG_ 2147491588 DBW_BrakeDriverActivity "Driver is pressing the brakes, which will switch the DBW system to Manual mode. This flag latches and will unlatch when AKit_BrkPdlCtrlEnblCmd goes back to false.


ROS Attribute: driver_activity
";
CM_ SG_ 2147491588 DBW_BrakeFault "Brake system has a fault, either from the vehicle itself or from an error in the request message from the AKit


ROS Attribute: fault_brake_system
";
CM_ SG_ 2147491588 DBW_BrakeRollingCntr "Watchdog alive rolling counter


ROS Attribute: rolling_counter
";
CM_ SG_ 2147491588 DBW_BrakePcntTorqueActual "actual brake torque. This value is in % of a fixed reference value. This reference value depends only on the type of vehicle. Contact New Eagle to determine the reference value for your vehicle make/model.

100% reference values for each vehicle platform:
Chrylser Pacifica: 100% = 9.8 m/s^2 deceleration on flat ground at curb weight.
Volvo VNR:\t  100% = 9.8 m/s^2 deceleration on flat ground at curb weight.
Toyota Prius:\t  100% = 6.0 m/s^2 deceleration on flat ground at curb weight.

ROS Attribute: brake_torque_actual
";
CM_ SG_ 2147491588 DBW_BrakeParkingBrkStatus "
ROS Attribute: parking_brake
";
CM_ SG_ 2147491588 DBW_BrakeInterventionActv "indicates traction control or ABS on the OEM vehicle is active


ROS Attribute: intervention_active
";
CM_ SG_ 2147491588 DBW_BrakeInterventionReady "indicates traction control or ABS on the OEM vehicle is ready (not disabled but not currently active either)


ROS Attribute: intervention_ready
";
CM_ SG_ 2147491588 DBW_BrakeCtrlType "Indicates whether the DBW kit is set to apply an open loop command (AKit responsible for performing all PID control),
 or requesting the DBW to apply PID control at the actuator level (turn wheel to a certain angle, or apply a certain amount of accel/brake torque & let AKit perform PID control on vehicle curvature/speed)
or requesting the DBW to perform all PID control at the vehicle level (control to a vehicle curvature and speed). If ReqType is 2, the requested speed will be taken from the signal AKit_SpeedReq in the AKit_AccelRequest message.
Some vehicles may not support all types!


ROS Attribute: control_type
";
CM_ BO_ 2147491589 "ROS Topic: /raptor_dbw_interface/gear_report";
CM_ SG_ 2147491589 DBW_PrndStateActual "
ROS Attribute: state
";
CM_ SG_ 2147491589 DBW_PrndStateReject "may make this an enum later, after more testing


ROS Attribute: reject
";
CM_ SG_ 2147491589 DBW_PrndDriverActivity "indicates the driver is turning the PRND shift knob


ROS Attribute: driver_override
";
CM_ SG_ 2147491589 DBW_PrndFault "PRND select system has a fault, either from the vehicle itself or from an error in the request message from the AKit


ROS Attribute: gear_select_system_fault
";
CM_ SG_ 2147491589 DBW_PrndCtrlEnabled "PRND select system is under by-wire control. Typically matches the autonomous mode, except in some emergency stop lost-communication scenarios


ROS Attribute: enabled
";
CM_ BO_ 2147491590 "ROS Topic: /raptor_dbw_interface/wheel_position_report";
CM_ SG_ 2147491590 DBW_WhlPulseCnt_FL "Wheel pulse counter


ROS Attribute: front_left
";
CM_ SG_ 2147491590 DBW_WhlPulseCnt_FR "Wheel pulse counter


ROS Attribute: front_right
";
CM_ SG_ 2147491590 DBW_WhlPulseCnt_RL "Wheel pulse counter


ROS Attribute: rear_left
";
CM_ SG_ 2147491590 DBW_WhlPulseCnt_RR "Wheel pulse counter


ROS Attribute: rear_right
";
CM_ SG_ 2147491590 DBW_WhlPulsesPerRev "Number of wheel pulses in one revolution (96 for the Pacifica & Grand Cherokee)


ROS Attribute: wheel_pulses_per_rev
";
CM_ BO_ 2147495682 "Must be sent continuously, even if you're not planning to enable this actuator.

ROS Topic: /raptor_dbw_interface/accelerator_pedal_cmd";
CM_ SG_ 2147495682 AKit_AccelPdlReq "Used when AKit_AccelReqType = 0.
For J1939 vehicles with TSC1 control (Volvo), this is a %-of-reference-torque.
For all other vehicles with physical pedal wiring intercepts (Pacifica), this is a %-of-pedal-position


ROS Attribute: pedal_cmd
";
CM_ SG_ 2147495682 AKit_AccelPdlEnblReq "AKit_GlobalByWireEnblReq must also be true before the DBW system will look at this signal.


ROS Attribute: enable
";
CM_ SG_ 2147495682 AKit_AccelPdlIgnoreDriverOvrd "
ROS Attribute: ignore
";
CM_ SG_ 2147495682 AKit_AccelPdlRollingCntr "0-15 rolling counter


ROS Attribute: rolling_counter
";
CM_ SG_ 2147495682 AKit_AccelReqType "Indicates whether the AKit is requesting the DBW kit to apply an open loop command (AKit responsible for performing all PID control),
 or requesting the DBW to apply PID control at the actuator level (turn wheel to a certain angle, or apply a certain amount of accel/brake torque & let AKit perform PID control on vehicle curvature/speed)
or requesting the DBW to perform all PID control at the vehicle level (control to a vehicle curvature and speed)
Some vehicles may not support all types! Refer to the **CtrlType feedback from the DBW module to ensure your vehicle supports a given mode


ROS Attribute: control_type
";
CM_ SG_ 2147495682 AKit_AccelPcntTorqueReq "Used when AKit_AccelReqType = 1. This mode allows the AKit to request a constant torque value and let the DBW system adjust the pedal position to meet that torque. 

This value is in % of a fixed reference value. This reference value depends only on the type of vehicle.

Note that the reference value is the same in the braking and AccelPdl control logic. Because any given vehicle's braking system is usually more powerful than it's acceleration system (powertrain), the DBW system will typically reach the max pedal position when only roughly 50% accel torque is requested, again depending on the make/model of the vehicle.

100% reference values for each vehicle platform:
Chrylser Pacifica: \t100% = 9.8 m/s^2 acceleration on flat ground at curb weight.
Volvo VNR:\t  \t100% = 9.8 m/s^2 acceleration on flat ground at curb weight.
Toyota Prius:\t  \t100% = 6.0 m/s^2 acceleration on flat ground at curb weight.
Jeep Grand Cherokee:\t100% = 8.1 m/s^2 acceleration on flat ground at curb weight.

ROS A";
CM_ SG_ 2147495682 AKit_SpeedReq "Used when AKit_AccelReqType = 2 AND Kit_BrakeCtrllReqType = 2. Both must be 2 because speed control will use both the gas and brake (although a test engineer can leave one of those 2 actuators in manual mode by setting it's ***EnbReq flag to zero, just like in other ***ReqType modes).


ROS Attribute: speed_cmd
";
CM_ SG_ 2147495682 AKit_SpeedModeRoadSlope "positive = vehicle facing uphill. Used to adjust the torque requested to meet a given speed (steeper slope requires more torque to hold a constant speed). If this signal is not available, you can send a constant value of zero and speed control will still function but the speed controller will have greater error on sloped surfaces. If internally calibrated to do so, the DBW may also use its own estimate of road slope IFF the AKit is sending exactly 0 for this signal.

The steepest grades in the world are 21 degrees, so this scaling will encompass all real-world roads.

If vehicle is traveling downhill in reverse (facing uphill), this should still be a positive value. the DBW will compensate for PRND direction.


ROS Attribute: road_slope
";
CM_ SG_ 2147495682 AKit_AccelPdlChecksum "J1850 checksum (initial value 0xFF, polynomial 0x11D)";
CM_ SG_ 2147495682 AKit_SpeedModeAccelLim "0 = infinite (no limit). When AKit_AccelReqType = 2 (speed control), the DBW will limit acceleration to this value.
If vehicle is in reverse, this signal will still limit the accelerator pedal value (not the brake)


ROS Attribute: accel_limit
";
CM_ SG_ 2147495682 AKit_SpeedModePosJerkLim "0 = infinite (no limit). When AKit_AccelReqType = 2 (speed control), the DBW will limit jerk (rate-of-change of torque) to this value.
If vehicle is in reverse, this signal will still limit the accelerator pedal value (not the brake)


ROS Attribute: ";
CM_ BO_ 2147495681 "Must be sent continuously, even if you're not planning to enable this actuator.

ROS Topic: /raptor_dbw_interface/global_enable_cmd";
CM_ SG_ 2147495681 AKit_GlobalEnblRollingCntr "0-15 rolling counter


ROS Attribute: rolling_counter
";
CM_ SG_ 2147495681 AKit_GlobalByWireEnblReq "Global flag to allow by-wire DBW operation. The AKit must send this AND individual actuator enable flags to control any vehicle actuator. Also, if DBW_MiscByWireEnbl goes to zero for any reason uring autonomous driving (driver override, fault, ignition turned off, etc), then this signal must be cycled from 1 to 0 and back to 1 before reenabling autonomous mode. This is in order to acknoledge that the reason for the disable has been addressed and the driver or autonomous system truly wants to return to autonomous operation


ROS Attribute: global_enable
";
CM_ SG_ 2147495681 AKit_EnblJoystickLimits "For safety & drivability, if this bit is asserted, the DBW system will assume the vehicle is in joystick demonstration mode. This will limit vehicle speed, relinearize the input requests, rate limit, and clip the various actuators to allow smoother and safer operation while a human is demonstrating DBW operation with a joystick that has a high sensitivity. When a real autonomous system is controlling the DBW (more precise than a human), this bit should not be asserted so that the DBW won't apply rate limits, clips, and vehicle speed limits.


ROS Attribute: enable_joystick_limits
";
CM_ SG_ 2147495681 AKit_SoftwareBuildNumber "Build number of the software that is currently running on the AKit system.


ROS Attribute: ecu_build_number
";
CM_ SG_ 2147495681 AKit_GlobalEnblChecksum "J1850 checksum (initial value 0xFF, polynomial 0x11D)";
CM_ BO_ 2147495686 "Must be sent continuously, even if you're not planning to enable this actuator.

ROS Topic: /raptor_dbw_interface/misc_cmd";
CM_ SG_ 2147495686 AKit_TurnSignalReq "Currently supported by Prius only. Contact New Eagle if you are interested in adding support for Hazards on a Pacifica or Volvo vehicle.


ROS Attribute: cmd
";
CM_ SG_ 2147495686 AKit_RightRearDoorReq "Requested state of the given door, if electronically controlled. Currently supported by the Pacifica, but not the Volvo VNR Truck or Prius.


ROS Attribute: door_request_right_rear
";
CM_ SG_ 2147495686 AKit_HighBeamReq "Request high beam headlights. Supported on Pacifica, Volvo, and Prius.


ROS Attribute: high_beam_cmd
";
CM_ SG_ 2147495686 AKit_FrontWiperReq "Some vehicles (Volvo) don't support 6 different intermittent speeds. Vovlo only supports 4 intermittent speeds.


ROS Attribute: front_wiper_cmd
";
CM_ SG_ 2147495686 AKit_RearWiperReq "Only if a rear wiper is equipped on the vehicle. Some vehicles may not support all speeds shown here.


ROS Attribute: rear_wiper_cmd
";
CM_ SG_ 2147495686 AKit_IgnitionReq "Currently supported by the Volvo base kit, and the Pacifica add-on option. Contact New Eagle if you are interested in adding support for Ignition on a Pacifica or Prius vehicle.

On both Volvo and Pacifica, the ignition can be controled from any autonomous mode because you typically can't get into automous mode until after ignition is on. Obviously, though, the DBW module must be awoken by some wake input other than the vehicle ignition before it can accept a command to go from Ignition Off to any other ignition state.

ROS Attribute: ignition_cmd
";
CM_ SG_ 2147495686 AKit_LeftRearDoorReq "Requested state of the given door, if electronically controlled. Currently supported by the Pacifica, but not the Volvo VNR Truck or Prius.


ROS Attribute: door_request_left_rear
";
CM_ SG_ 2147495686 AKit_LiftgateDoorReq "Requested state of the given door, if electronically controlled. Currently supported by the Pacifica, but not the Volvo VNR Truck or Prius.


ROS Attribute: door_request_lift_gate
";
CM_ SG_ 2147495686 AKit_BlockBasicCruiseCtrlBtns "Allows the AKit to tell the DBW to block the driver's buttons presses from passing through the DBW gateway and enabling the vehicle's features. This exists in case the AKit wants to use those inputs for it's own purposes without the vehicle's OEM cruise control system activating


ROS Attribute: block_standard_cruise_buttons
";
CM_ SG_ 2147495686 AKit_BlockAdapCruiseCtrlBtns "Allows the AKit to tell the DBW to block the driver's buttons presses from passing through the DBW gateway and enabling the vehicle's features. This exists in case the AKit wants to use those inputs for it's own purposes without the vehicle's OEM cruise control system activating


ROS Attribute: block_adaptive_cruise_buttons
";
CM_ SG_ 2147495686 AKit_BlockTurnSigStalkInpts "Allows the AKit to tell the DBW to block the driver's buttons presses from passing through the DBW gateway and enabling the vehicle's features. This exists in case the AKit wants to use those inputs for it's own purposes without the vehicle's OEM cruise control system activating


ROS Attribute: block_turn_signal_stalk
";
CM_ SG_ 2147495686 AKit_OtherRollingCntr "0-15 rolling counter


ROS Attribute: rolling_counter
";
CM_ SG_ 2147495686 AKit_OtherChecksum "J1850 checksum (initial value 0xFF, polynomial 0x11D)";
CM_ SG_ 2147495686 AKit_HornReq "Currently supported by Prius & Volvo only. Contact New Eagle if you are interested in adding support for Horn on a Pacifica vehicle.";
CM_ SG_ 2147495686 AKit_LowBeamReq "Currently supported by Prius & Volvo only. Contact New Eagle if you are interested in adding support for Low Beam control on a Pacifica (in addition to the automatic-low-beam feature on the OEM vehicle).

They will turn on if the running lights are requested to be on.";
CM_ SG_ 2147495686 AKit_DiffLock "Engage differential axle lock.";
CM_ SG_ 2147495686 AKit_OtherLightsReq "Used to actuate any other accesory lighting";
CM_ BO_ 2147495683 "Must be sent continuously, even if you're not planning to enable this actuator.

ROS Topic: /raptor_dbw_interface/steering_cmd";
CM_ SG_ 2147495683 AKit_SteeringWhlAngleReq "counterclockwise = positive. Not all vehicles support the full range of travel. The Pacifica supports +/- 540deg, the Volvo VNR supports +/-750deg, Prius +/-500deg, and the Grand Cherokee +/-560 deg. See the signal DBW_SteeringWhlAngleDes to see if the DBW system is clipping an out-of-range request for your vehicle.


ROS Attribute: angle_cmd
";
CM_ SG_ 2147495683 AKit_SteeringWhlAngleVelocityLim "0 = infinite rate limit. Used only when SteeringWhlReqType = 1 or 2.


ROS Attribute: angle_velocity
";
CM_ SG_ 2147495683 AKit_SteerCtrlEnblReq "AKit_GlobalByWireEnblReq must also be true before the DBW system will look at this signal.


ROS Attribute: enable
";
CM_ SG_ 2147495683 AKit_SteerRollingCntr "0-15 rolling counter


ROS Attribute: rolling_counter
";
CM_ SG_ 2147495683 AKit_SteeringWhlIgnoreDriverOvrd "
ROS Attribute: ignore
";
CM_ SG_ 2147495683 AKit_SteeringWhlPcntTrqReq "requested steering wheel torque as a percent of a fixed reference value. This reference value depends only on the type of vehicle. Contact New Eagle to determine the reference value for your vehicle make/model.

Used in lieu of AKit_SteeringWhlAnglReq if the AKit is going to handle the PID control to acheive a desired position.

100% reference values for each vehicle platform:
Chrylser Pacifica: 100% = 105 Nm
Volvo VNR:\t  100% = 40 Nm
Toyota Prius:\t  not applicable, torque mode not supported

ROS Attribute: torque_cmd
";
CM_ SG_ 2147495683 AKit_SteeringReqType "Indicates whether the AKit is requesting the DBW kit to apply an open loop command (AKit responsible for performing all PID control),
 or requesting the DBW to apply PID control at the actuator level (turn wheel to a certain angle, or apply a certain amount of accel/brake torque & let AKit perform PID control on vehicle curvature/speed)
or requesting the DBW to perform all PID control at the vehicle level (control to a vehicle curvature and speed)
Some vehicles may not support all types! Refer to the **CtrlType feedback from the DBW module to ensure your vehicle supports a given mode


ROS Attribute: control_type
";
CM_ SG_ 2147495683 AKit_SteeringVehCurvatureReq "Used when AKit_SteeringWhlReqType = 2 (vehicle-level closed loop control). Curvature is the inverse of turn radius, such that 0 curvature = straight. Counterclockwise = positive


ROS Attribute: vehicle_curvature_cmd
";
CM_ SG_ 2147495683 AKit_SteeringChecksum "J1850 checksum (initial value 0xFF, polynomial 0x11D)";
CM_ BO_ 2147495684 "Must be sent continuously, even if you're not planning to enable this actuator.

ROS Topic: /raptor_dbw_interface/brake_cmd";
CM_ SG_ 2147495684 AKit_BrakePedalReq "Used when AKit_BrakeCtrlReqType = 0


ROS Attribute: pedal_cmd
";
CM_ SG_ 2147495684 AKit_BrakeRollingCntr "0-15 rolling counter


ROS Attribute: rolling_counter
";
CM_ SG_ 2147495684 AKit_BrakeCtrlEnblReq "AKit_GlobalByWireEnblReq must also be true before the DBW system will look at this signal.


ROS Attribute: enable
";
CM_ SG_ 2147495684 AKit_BrakeCtrlReqType "Indicates whether the AKit is requesting the DBW kit to apply an open loop command (AKit responsible for performing all PID control),
 or requesting the DBW to apply PID control at the actuator level (turn wheel to a certain angle, or apply a certain amount of accel/brake torque & let AKit perform PID control on vehicle curvature/speed)
or requesting the DBW to perform all PID control at the vehicle level (control to a vehicle curvature and speed). If ReqType is 2, the requested speed will be taken from the signal AKit_SpeedReq in the AKit_AccelRequest message.
Some vehicles may not support all types!


ROS Attribute: control_type
";
CM_ SG_ 2147495684 AKit_BrakePcntTorqueReq "Used when AKit_BrakeCtrlReqType = 1. This mode allows the AKit to request a constant torque value and let the DBW system adjust the pedal position to meet that torque. 

This value is in % of a fixed reference value. This reference value depends only on the type of vehicle. Contact New Eagle to determine the reference value for your vehicle make/model.

100% reference values for each vehicle platform:
Chrylser Pacifica: \t100% = 9.8 m/s^2 deceleration on flat ground at curb weight.
Volvo VNR:\t  \t100% = 9.8 m/s^2 deceleration on flat ground at curb weight.
Toyota Prius:\t\t100% = 6.0 m/s^2 deceleration on flat ground at curb weight.
Jeep Grand Cherokee:\t100% = 8.1 m/s^2 acceleration on flat ground at curb weight.

ROS Attribute: torque_cmd
";
CM_ SG_ 2147495684 AKit_SpeedModeDecelLim "0 = infinite (no limit). When AKit_AccelReqType = 2 (speed control), the DBW will limit decceleration to this value.
If vehicle is in reverse, this signal will still limit the brake pedal value (not the accelerator).
Overshoot & settling time requirements cannot be guaranteed with a limit above 7.5m/s^2. The no-limit value, or anything above 7.5m/s^2 should only be used for emergency braking.


ROS Attribute: decel_limit
";
CM_ SG_ 2147495684 AKit_BrakeChecksum "J1850 checksum (initial value 0xFF, polynomial 0x11D)";
CM_ SG_ 2147495684 AKit_SpeedModeNegJerkLim "0 = infinite (no limit). When AKit_BrakeCtrlReqType = 2 (speed control), the DBW will limit negative jerk (rate-of-change of torque) to this value.
If vehicle is in reverse, this signal will still limit the brake pedal value (not the accelerator).
Overshoot & settling time requirements cannot be guaranteed with a limit below X.Xm/s^2.


ROS Attribute:";
CM_ SG_ 2147495684 AKit_ParkingBrkReq "Currently support only as an add-on option to the Pacifica. Contact New Eagle if you are interested in adding this option to a different vehicle platform.

On the Pacifica, the parking brake can be applied in any ignition state and any autonomous state. the parking brake can be released in any autonomous state, but can NOT be released if the vehicle ignition is Off or Accessory. it must be in Run to release the parking brake.";
CM_ BO_ 2147495685 "Must be sent continuously, even if you're not planning to enable this actuator.

ROS Topic: /raptor_dbw_interface/gear_cmd ";
CM_ SG_ 2147495685 AKit_PrndStateReq "PRND shifter position request


ROS Attribute: cmd
";
CM_ SG_ 2147495685 AKit_PrndRollingCntr "0-15 rolling counter


ROS Attribute: rolling_counter
";
CM_ SG_ 2147495685 AKit_PrndCtrlEnblReq "AKit_GlobalByWireEnblReq must also be true before the DBW system will look at this signal.


ROS Attribute: enable
";
CM_ SG_ 2147495685 AKit_PrndChecksum "J1850 checksum (initial value 0xFF, polynomial 0x11D)";
CM_ BO_ 2147491599 "ROS Topic: /raptor_dbw_interface/driver_input_report";
CM_ SG_ 2147491599 DBW_OccupAnyDoorOrHoodAjar "
ROS Attribute: door_or_hood_ajar
";
CM_ SG_ 2147491599 DBW_OccupAnyAirbagDeployed "true if there has been a crash


ROS Attribute: airbag_deployed
";
CM_ SG_ 2147491599 DBW_OccupAnySeatbeltUnbuckled "indicates seatbelt warning lamp is on


ROS Attribute: any_seatbelt_unbuckled
";
CM_ SG_ 2147491599 DBW_DrvInptCruiseResumeBtn "0 = not pressed, 1 = pressed. Cruise buttons are used to enable autonomous driving if pressed in a special combination


ROS Attribute: cruise_resume_button
";
CM_ SG_ 2147491599 DBW_DrvInptCruiseCancelBtn "0 = not pressed, 1 = pressed. Cruise buttons are used to enable autonomous driving if pressed in a special combination


ROS Attribute: cruise_cancel_button
";
CM_ SG_ 2147491599 DBW_DrvInptCruiseAccelBtn "0 = not pressed, 1 = pressed. Cruise buttons are used to enable autonomous driving if pressed in a special combination


ROS Attribute: bool cruise_accel_button
";
CM_ SG_ 2147491599 DBW_DrvInptCruiseDecelBtn "0 = not pressed, 1 = pressed. Cruise buttons are used to enable autonomous driving if pressed in a special combination


ROS Attribute: cruise_decel_button
";
CM_ SG_ 2147491599 DBW_DrvInptCruiseOnOffBtn "0 = not pressed, 1 = pressed. Cruise buttons are used to enable autonomous driving if pressed in a special combination


ROS Attribute: cruise_on_off_button
";
CM_ SG_ 2147491599 DBW_DrvInptAccOnOffBtn "0 = not pressed, 1 = pressed. ACC = adaptive cruise


ROS Attribute: adaptive_cruise_on_off_button
";
CM_ SG_ 2147491599 DBW_DrvInptAccIncDistBtn "0 = not pressed, 1 = pressed. ACC = adaptive cruise


ROS Attribute: adaptive_cruise_increase_distance_button
";
CM_ SG_ 2147491599 DBW_DrvInptAccDecDistBtn "0 = not pressed, 1 = pressed. ACC = adaptive cruise


ROS Attribute: adaptive_cruise_decrease_distance_button
";
CM_ SG_ 2147491599 DBW_DrvInptHiBeam "
ROS Attribute: high_beam_headlights
";
CM_ SG_ 2147491599 DBW_DrvInptTurnSignal "
ROS Attribute: turn_signal
";
CM_ SG_ 2147491599 DBW_DrvInptWiper "
ROS Attribute: wiper
";
CM_ SG_ 2147491599 DBW_DrvInputStrWhlBtnA "0 = not pressed, 1 = pressed. This button varies across New Eagle vehicle platforms (Pacifica, Prius, Volvo, etc) because all steering wheels have different numbers and types of buttons available on the CAN bus. Contact New Eagle to find out which buttons are used on your platform, or press all the steering wheel buttons and see which of these signals respond.";
CM_ SG_ 2147491599 DBW_DrvInputStrWhlBtnB "0 = not pressed, 1 = pressed. This button varies across New Eagle vehicle platforms (Pacifica, Prius, Volvo, etc) because all steering wheels have different numbers and types of buttons available on the CAN bus. Contact New Eagle to find out which buttons are used on your platform, or press all the steering wheel buttons and see which of these signals respond.";
CM_ SG_ 2147491599 DBW_DrvInputStrWhlBtnC "0 = not pressed, 1 = pressed. This button varies across New Eagle vehicle platforms (Pacifica, Prius, Volvo, etc) because all steering wheels have different numbers and types of buttons available on the CAN bus. Contact New Eagle to find out which buttons are used on your platform, or press all the steering wheel buttons and see which of these signals respond.";
CM_ SG_ 2147491599 DBW_DrvInputStrWhlBtnD "0 = not pressed, 1 = pressed. This button varies across New Eagle vehicle platforms (Pacifica, Prius, Volvo, etc) because all steering wheels have different numbers and types of buttons available on the CAN bus. Contact New Eagle to find out which buttons are used on your platform, or press all the steering wheel buttons and see which of these signals respond.";
CM_ SG_ 2147491599 DBW_DrvInputStrWhlBtnE "0 = not pressed, 1 = pressed. This button varies across New Eagle vehicle platforms (Pacifica, Prius, Volvo, etc) because all steering wheels have different numbers and types of buttons available on the CAN bus. Contact New Eagle to find out which buttons are used on your platform, or press all the steering wheel buttons and see which of these signals respond.";
CM_ BO_ 2147491591 "ROS Topic: /raptor_dbw_interface/tire_pressure_report";
CM_ SG_ 2147491591 DBW_TirePressRR "pacifica scaling goes from 0 to 126, 1 psi per bit. convert to kpa for standard units here.


ROS Attribute: rear_right
";
CM_ SG_ 2147491591 DBW_TirePressRL "pacifica scaling goes from 0 to 126, 1 psi per bit. convert to kpa for standard units here.


ROS Attribute: rear_left
";
CM_ SG_ 2147491591 DBW_TirePressFR "pacifica scaling goes from 0 to 126, 1 psi per bit. convert to kpa for standard units here.


ROS Attribute: front_right
";
CM_ SG_ 2147491591 DBW_TirePressFL "pacifica scaling goes from 0 to 126, 1 psi per bit. convert to kpa for standard units here.


ROS Attribute: front_left
";
CM_ BO_ 2147491592 "ROS Topic: /raptor_dbw_interface/vin";
CM_ SG_ 2147491592 DBW_VinMultiplexor "message multiplexor";
CM_ BO_ 2147491593 "Message ID reserved for future additions

ROS Topic: N/A";
CM_ BO_ 2147491594 "IMU = Intertial Measurement Unit

ROS Topic: /raptor_dbw_interface/imu/data_raw";
CM_ SG_ 2147491594 DBW_ImuYawRate "postive = left.


ROS Attribute: angular_velocity.z
";
CM_ SG_ 2147491594 DBW_ImuAccelX "postive = forward.


ROS Attribute: linear_acceleration.x
";
CM_ SG_ 2147491594 DBW_ImuAccelY "positive = left.


ROS Attribute: linear_acceleration.y
";
CM_ BO_ 2147491595 "Some vehicles send an RPM, others a speed in km/h. Both are multiplexed into this message so that a common DBC can be maintained for New Eagle DBW vehicles

ROS Topic: /raptor_dbw_interface/wheel_speed_report";
CM_ SG_ 2147491595 DBW_WhlSpd_RR "positive is forward. Used on Pacifica.


ROS Attribute: rear_right
";
CM_ SG_ 2147491595 DBW_WhlSpd_RL "positive is forward. Used on Pacifica.


ROS Attribute: rear_left
";
CM_ SG_ 2147491595 DBW_WhlSpd_FR "positive is forward. Used on Pacifica.


ROS Attribute: front_right
";
CM_ SG_ 2147491595 DBW_WhlSpd_FL "positive is forward. Used on Pacifica.


ROS Attribute: front_left
";
CM_ BO_ 2147491600 "ROS Topic: /raptor_dbw_interface/surround_report";
CM_ SG_ 2147491600 DBW_Reserved2 "This signal is reserved for future addition of a gateway module to read the front ACC radar distance from the dedicated radar/camera CAN bus.


ROS Attribute: front_radar_object_distance
";
CM_ SG_ 2147491600 DBW_Reserved3 "This signal is reserved for a validity bit for the future addition of a gateway module to read the front ACC radar distance from the dedicated radar/camera CAN bus. This will be false when the Radar module is disabled or faulted.


ROS Attribute: front_radar_distance_valid
";
CM_ SG_ 2147491600 DBW_SonarVld "indicates if the values from the ultrasonic parking sensors are valid. This will be false when the Park Assist module is disabled or faulted.


ROS Attribute: parking_sonar_data_valid
";
CM_ SG_ 2147491600 DBW_SonarArcNumRR "
ROS Attribute: rear_right
";
CM_ SG_ 2147491600 DBW_SonarArcNumRL "
ROS Attribute: rear_left
";
CM_ SG_ 2147491600 DBW_SonarArcNumRC "
ROS Attribute: rear_center
";
CM_ SG_ 2147491600 DBW_SonarArcNumFR "
ROS Attribute: front_right
";
CM_ SG_ 2147491600 DBW_SonarArcNumFL "
ROS Attribute: front_left
";
CM_ SG_ 2147491600 DBW_SonarArcNumFC "
ROS Attribute: front_center
";
CM_ SG_ 2147491600 DBW_SonarRearDist "distance to nearest rear obstacle.


ROS Attribute: rear_radar_object_distance
";
CM_ BO_ 1807 "ASCII names of faults present in the DBW system

ROS Topic: N/A";
CM_ SG_ 1807 FltTxt_PageNum "Multiplexor";
CM_ SG_ 1807 FltTxt_FaultId "Index of the fault in Raptor. This number is the output of the Raptor Fault Iterator block. this array can also be accessed by the raptor_get_faults() command in MATLAB.";
CM_ SG_ 1807 FltTxt_NumPages "number of pages in the packet for this one fault, varies depending on how many characters in the fault name";
CM_ SG_ 1807 FltTxt_FaultStatus "status of the fault referenced in the current packet";
CM_ SG_ 1807 FltTxt_FaultSetRuntime "timestamp (during current key cycle) when the fault set";
CM_ SG_ 1807 FltTxt_CRC "custom checksum of the fault packet";
CM_ SG_ 1807 FltTxt_CurrentRuntime "current run time (in the current key cycle)";
CM_ BO_ 2147491601 "Voltage & Current info for the Low Voltage (12V) system

ROS Topic: /raptor_dbw_interface/low_voltage_system_report";
CM_ SG_ 2147491601 DBW_LvDbwBattVlt "Voltage of the DBW auxiliary battery. Will typically match DBW_LvVehBattVlt, except in a case where the DBW system has opened the LV battery contactor to prevent draining both batteries.


ROS Attribute: dbw_battery_volts
";
CM_ SG_ 2147491601 DBW_LvVehBattVlt "Voltage of the Vehicle's main 12V system. Will typically match DBW_LvDbwBattVlt, except in a case where the DBW system has opened the LV battery contactor to prevent draining both batteries.


ROS Attribute: vehicle_battery_volts
";
CM_ SG_ 2147491601 DBW_LvBattCurr "Current being drawn from the vehicle's OEM 12V battery. This is a measured value on the Pacifica (doesn't include any auxiliary batteries added with the DBW kit). All other vehicles may not support this value or simply report a worst-case estimate based on battery voltage.


ROS Attribute: battery_current
";
CM_ SG_ 2147491601 DBW_LvDcdcCurr "Current being drawn from the optional DCDC converter supplied by New Eagle. This does not include the current produced by a hybrid vehicle's OEM DCDC converter.


ROS Attribute: dcdc_current
";
CM_ SG_ 2147491601 DBW_LvAlternatorCurr "Placeholder. Currently, New Eagle's DBW vehicles do not support this measurement.


ROS Attribute: alternator_current
";
CM_ SG_ 2147491601 DBW_LvInvtrContactorCmd "True when the DBW system is commanding the relay closed between the vehicle's 12V system and the inverter. The inverter draws 200mA when off, so this contactor is just controlled to open when the DBW module is off


ROS Attribute: inverter_contactor
";
CM_ BO_ 2147491602 "ROS Topic: /raptor_dbw_interface/brake_2_report";
CM_ SG_ 2147491602 DBW_BrakePress_bar "not all vehicles will have the maximum resolution. the scaling and max value are set so that this signal wont need to change between vehicles with hydraulic brakes and vehicles with air brakes.

For example, the Pacifica reports pressure in bar with a range of 0-200bar and resolution of 0.1 bar/bit. The Volvo VNR reports pressure with a range of 0-10bar with a resolution of 0.04 bar/bit


ROS Attribute: brake_pressure
";
CM_ SG_ 2147491602 DBW_RoadSlopeEstimate "positive = traveling uphill. Used to adjust the torque requested to meet a given speed (steeper slope requires more torque to hold a constant speed). If a non-zero value is sent over the CAN bus in the message AKit_SpeedModeRoadSlope, the DBW will use that value. If 0 slope is sent from the AKit, the DBW will use zero OR estimate the slope internally (depends on how the internal DBW calibrations are set).

The steepest grades in the world are 21 degrees, so this scaling will encompass all real-world roads.

If vehicle is traveling downhill in reverse (facing uphill), this will still be a positive value.


ROS Attribute: estimated_road_slope
";
CM_ SG_ 2147491602 DBW_SpeedSetpt "setpoint of the speed controller after any overrides. Used to plot & compare data against actual vehicle speed";
CM_ BO_ 2147491603 "ROS Topic: /raptor_dbw_interface/steering_2_report";
CM_ SG_ 2147491603 DBW_SteeringVehCurvatureAct "Curvature is the inverse of turn radius, such that 0 curvature = straight. Counterclockwise = positive


ROS Attribute: vehicle_curvature_actual
";
CM_ SG_ 2147491603 DBW_SteerTrq_Driver "% of the max torque the driver can apply. The max changes based on the vehicle platform.

Chrylser Pacifica: 100% = 5 Nm
Volvo VNR:\t  100% = 128 (unitless)
Toyota Prius:\t  100% = 700 (unitless)";
CM_ SG_ 2147491603 DBW_SteerTrq_Motor "% of the max torque the motor can apply. The max changes based on the vehicle platform. See the DBW User Manual to see what the max value is on your vehicle.

Chrylser Pacifica: 100% = 105 Nm
Volvo VNR:\t  100% = 40 Nm
Toyota Prius:\t  100% = 20,000 (unitless)";
CM_ SG_ 2147491603 DBW_PacificaSteerTrq "For development purposes only";
CM_ BO_ 2147491604 "Status feedback for the various actuators commanded via AKit_OtherActuators. These will set if either the driver turns them on OR the autonomous system.

ROS Topic: /raptor_dbw_interface/other_actuators_report";
CM_ SG_ 2147491604 DBW_OtherActRollingCntr "Watchdog alive rolling counter";
CM_ BO_ 2147491605 "ROS Topic: /raptor_dbw_interface/fault_actions_report";
CM_ SG_ 2147491605 DBW_EmgrStopBtnPrssd "Indicates if the in-vehicle ESTOP is pressed.";
CM_ SG_ 2147491605 DBW_RemoteEmgrStopBtnPrssd "Indicates if the remote ESTOP is pressed. The presense of this ESTOP is vehicle dependent. Value of 0x3 indicates the sensor is not present.";
CM_ BO_ 2147491606 "Supported only on Grand Cherokee, unless a standalone GPS is added to the base DBW kit on other vehicles. Low-res GPS reference point broadcasted slowly (doesnt change often). Higher res information will be sent in the DBW_GpsRemainder message in units of meters, relative to this reference

The DBW module splits the GPS reading into a Reference and Remainder because most embedded modules only support single floating-point resolution, not double floating-point. With a single data type, the resolution near 180 degrees of longitude is +/- several meters per bit. The Reference/Remainder approach allows the single datatype (or uint32 in this case) to have a resolution of 0.001 m/bit at 180degrees longitude. Note that the actual resolution of the GPS sensor may be worse than 0.001 m/bit, depending on what GPS sensor is used in a given vehicle platform. However, this CAN message will be able to support all types of GPS sensors without changing the scaling of this message.

ROS Topic: /raptor";
CM_ SG_ 2147491606 DBW_GpsRefLat "Supported only on Grand Cherokee, unless a standalone GPS is added to the base DBW kit on other vehicles. 

Low-res GPS reference point TX'ed slowly. Higher res information will be sent in the DBW_GpsRemainder message in units of meters, relative to this reference

0.005deg is about 555meters. ";
CM_ SG_ 2147491606 DBW_GpsRefLong "Supported only on Grand Cherokee, unless a standalone GPS is added to the base DBW kit on other vehicles.

Low-res GPS reference point  TX'ed slowly. Higher res information will be sent in the DBW_GpsRemainder message in units of meters, relative to this reference.

0.005deg is about 555meters. ";
CM_ BO_ 2147491607 "Supported only on Grand Cherokee, unless a standalone GPS is added to the base DBW kit on other vehicles. Position, in meters, relative to the GpsReference sent in the other message.

The DBW module splits the GPS reading into a Reference and Remainder because most embedded modules only support single floating-point resolution, not double floating-point. With a single data type, the resolution near 180 degrees of longitude is +/- several meters per bit. The Reference/Remainder approach allows the single datatype (or uint32 in this case) to have a resolution of 0.001 m/bit at 180degrees longitude. Note that the actual resolution of the GPS sensor may be worse than 0.001 m/bit, depending on what GPS sensor is used in a given vehicle platform. However, this CAN message will be able to support all types of GPS sensors without changing the scaling of this message.

ROS Topic: /raptor_dbw_interface/gps_remainder_report";
CM_ SG_ 2147491607 DBW_GpsRemainderLat "Supported only on Grand Cherokee, unless a standalone GPS is added to the base DBW kit on other vehicles.

hi-res remainder from the reference signal, converted to meters. The meters conversion uses the basic Haversine formula, assuming 111,000m per deg latitude, and 111,321m per deg longitude at the equator";
CM_ SG_ 2147491607 DBW_GpsRemainderLong "Supported only on Grand Cherokee, unless a standalone GPS is added to the base DBW kit on other vehicles.

hi-res remainder from the reference signal, converted to meters. The meters conversion uses the basic Haversine formula, assuming 111,000m per deg latitude, and 111,321m per deg longitude at the equator";
CM_ BO_ 2147495687 "Must be sent continuously, even if you're not planning to enable this actuator.

ROS Topic: /raptor_dbw_interface/dump_bed_cmd";
CM_ SG_ 2147495687 AKit_DumpBedReqType "Req Type Mode lets you select the different modes from the dump bed lever. Req Type Angle does closed loop angle control.";
CM_ SG_ 2147495687 AKit_DumpBedLeverPercentReq "Used when reqType == Mode (0) and in either lower or raise mode. This is the percent from 0-100% for lower or rasie, so 50% raise is faster than 30% raise.";
CM_ SG_ 2147495687 AKit_DumpBedVelocityLimit "0 = infinite rate limit. Used only when DumpBedReqType = 1 or 0 and using raise/lower mode.";
CM_ BO_ 2147495689 "Must be sent continuously, even if you're not planning to enable this actuator.

ROS Topic: /raptor_dbw_interface/articulation_cmd";
CM_ SG_ 2147495689 AKit_ArticulationReqType "Only Angle is available right now";
CM_ SG_ 2147495689 AKit_ArticulationVelocityLimit "0 = infinite rate limit. Used only when ArticulationReqType = 1

";
CM_ BO_ 2147495688 "Must be sent continuously, even if you're not planning to enable this actuator.

ROS Topic: /raptor_dbw_interface/engine_cmd";
CM_ SG_ 2147495688 AKit_EngineModeReq "In order to change states, you must send No Request first. Ex: [No Request -> Engine On -> No Request -> Engine Off] will crank the engine and go to key on then it will turn off the engine and go to key off.";
CM_ SG_ 2147495688 AKit_EngineReqType "Req Type 0 lets you command the state of the key switch";
CM_ BO_ 2147491616 "supported only on dump trucks

ROS Topic: /raptor_dbw_interface/engine_report";
CM_ SG_ 2147491616 DBW_EngineKeyStateMismatch "idicates the state of the key state in relation to the ignition of the vehilce";
CM_ BO_ 2147495690 "Must be sent continuously, even if you're not planning to enable this actuator.

ROS Topic: /raptor_dbw_interface/action_cmd";
CM_ SG_ 2147495690 AKit_ActionVehStopReq "This causes the vehicle stop and go into park. The DBW Kit must be engaged for this action to take place.";
CM_ SG_ 2147495690 AKit_ActionEmergencyBrkReq "This applies the emergency brake to the system. Do not use this unless absolutely required.";
CM_ BO_ 2147491617 "supported only for articulated vehicles

ROS Topic: /raptor_dbw_interface/articulation_report";
CM_ SG_ 2147491617 DBW_ArticulationAngleAct "clockwise or right is positive";
CM_ BO_ 2147491618 "supported only for dump trucks

ROS Topic: /raptor_dbw_interface/dump_bed_report";
CM_ BO_ 2147491619 "ROS Topic: /raptor_dbw_interface/action_report";
CM_ BO_ 2147491620 "ROS Topic: /raptor_dbw_interface/dump_bed_2_report";
VAL_ 2147491585 DBW_MiscByWireEnabled 0 "ManualMode" 1 "DriveByWireMode" ;
VAL_ 2147491585 DBW_MiscByWireReady 0 "Not_Ready" 1 "Ready" ;
VAL_ 2147491586 DBW_AccelCtrlType 0 "Open Loop (Pedal %-Positon)" 1 "Actuator-Level Closed Loop (Accelerator %-Torque)" 2 "Vehicle-Level Closed Loop (Vehicle Speed)" ;
VAL_ 2147491587 DBW_SteeringCtrlType 0 "Open Loop (Steering %-Torque)" 1 "Actuator-Level Closed Loop (Steering Wheel Angular Position)" 2 "Vehicle-Level Closed Loop (Vehicle Curvature)" ;
VAL_ 2147491588 DBW_BrakeParkingBrkStatus 0 "Reserved" 1 "Off" 2 "On" 3 "Fault" ;
VAL_ 2147491588 DBW_BrakeCtrlType 0 "Open Loop (Pedal %-Positon)" 1 "Actuator-Level Closed Loop (Brake %-Torque)" 2 "Vehicle-Level Closed Loop (Vehicle Speed)" ;
VAL_ 2147491589 DBW_PrndStateActual 0 "No Request" 1 "Park" 2 "Reverse - R1" 3 "Neutral" 4 "Drive" 5 "Low" 6 "Manual" 11 "1" 12 "2" 13 "3" 14 "4" 15 "5" 16 "6" 17 "7" 18 "8" 19 "9" 20 "10" 128 "R2" 255 "SNA" ;
VAL_ 2147491589 DBW_PrndStateDes 0 "No Request" 1 "Park" 2 "Reverse - R1" 3 "Neutral" 4 "Drive" 5 "Low" 6 "Manual" 11 "1" 12 "2" 13 "3" 14 "4" 15 "5" 16 "6" 17 "7" 18 "8" 19 "9" 20 "10" 128 "R2" 255 "SNA" ;
VAL_ 2147495682 AKit_AccelReqType 0 "Open Loop (Pedal %-Positon)" 1 "Actuator-Level Closed Loop (Accelerator %-Torque)" 2 "Vehicle-Level Closed Loop (Vehicle Speed)" ;
VAL_ 2147495681 AKit_EnblJoystickLimits 0 "Fully Autonomous Control" 1 "Joystick Control Mode" ;
VAL_ 2147495686 AKit_TurnSignalReq 0 "Off" 1 "Left" 2 "Right" 3 "Hazards" ;
VAL_ 2147495686 AKit_RightRearDoorReq 0 "NoRequest" 1 "Close Door" 2 "Open Door" 3 "Undefined" ;
VAL_ 2147495686 AKit_HighBeamReq 0 "No Request" 1 "High Beam If Lights Already On" 2 "Force High Beam On" 3 "Reserved (Force Off Not Supported)" ;
VAL_ 2147495686 AKit_FrontWiperReq 0 "Off" 1 "Wiper_Intermittent1" 2 "Wiper_Intermittent2" 3 "Wiper_Intermittent3" 4 "Wiper_Intermittent4" 5 "Wiper_Intermittent5" 6 "Wiper_Intermittent6" 11 "Wiper_ConstantLowSpd" 12 "Wiper_ConstantHighSpd" 13 "Wiper_WashBrief" 14 "Wiper_WashContinuous" ;
VAL_ 2147495686 AKit_RearWiperReq 0 "Off" 1 "Wiper_Intermittent1" 11 "Wiper_ConstantLowSpd" 12 "Wiper_ConstantHighSpd" 13 "Wiper_WashBrief" 14 "Wiper_WashContinuous" ;
VAL_ 2147495686 AKit_IgnitionReq 0 "No Request (Use Key Position)" 1 "Off (Supported on Pacifica but not Volvo)" 2 "Accessory (Supported on Pacifica but not Volvo)" 3 "Run" 4 "Crank" ;
VAL_ 2147495686 AKit_LeftRearDoorReq 0 "No Request" 1 "Close Door" 2 "Open Door" 3 "Undefined" ;
VAL_ 2147495686 AKit_LiftgateDoorReq 0 "No Request" 1 "Close Door" 2 "Open Door" 3 "Undefined" ;
VAL_ 2147495686 AKit_BlockBasicCruiseCtrlBtns 0 "Pass Through" 1 "Block" ;
VAL_ 2147495686 AKit_BlockAdapCruiseCtrlBtns 0 "Pass Through" 1 "Block" ;
VAL_ 2147495686 AKit_BlockTurnSigStalkInpts 0 "Pass Through" 1 "Block" ;
VAL_ 2147495686 AKit_HornReq 0 "No Request" 1 "Horn On" ;
VAL_ 2147495686 AKit_LowBeamReq 0 "No Request" 1 "Low Beam if lights already on" 2 "On" 3 "Reserved" ;
VAL_ 2147495686 AKit_DoorLockReq 0 "DoorLock_NoRequest" 1 "Unlock_Doors" 2 "Lock_Doors" ;
VAL_ 2147495686 AKit_RunningLightsReq 0 "No Request" 1 "Reserved (Auto mode not supported)" 2 "Running Lights On" ;
VAL_ 2147495686 AKit_ModeLight_Red 1 "On" 0 "Off" ;
VAL_ 2147495686 AKit_ModeLight_Yellow 1 "On" 0 "Off" ;
VAL_ 2147495686 AKit_ModeLight_Green 1 "On" 0 "Off" ;
VAL_ 2147495686 AKit_ModeLight_Blue 1 "On" 0 "Off" ;
VAL_ 2147495686 AKit_DiffLock 1 "On" 0 "Off" ;
VAL_ 2147495686 AKit_OtherLightsReq 0 "No Request" 1 "Other lights if lights already on" 2 "On" 3 "Reserved" ;
VAL_ 2147495683 AKit_SteeringReqType 0 "Open Loop (Steering %-Torque)" 1 "Actuator-Level Closed Loop (Steering Wheel Angular Position)" 2 "Vehicle-Level Closed Loop (Vehicle Curvature)" ;
VAL_ 2147495684 AKit_BrakeCtrlReqType 0 "Open Loop (Pedal %-Positon)" 1 "Actuator-Level Closed Loop (Brake %-Torque)" 2 "Vehicle-Level Closed Loop (Vehicle Speed)" ;
VAL_ 2147495684 AKit_ParkingBrkReq 0 "No Request" 1 "Off" 2 "On" ;
VAL_ 2147495685 AKit_PrndStateReq 0 "No Request" 1 "Park" 2 "Reverse - R1" 3 "Neutral" 4 "Drive" 5 "Low" 6 "Manual" 11 "1" 12 "2" 13 "3" 14 "4" 15 "5" 16 "6" 17 "7" 18 "8" 19 "9" 20 "10" 128 "R2" 255 "SNA" ;
VAL_ 2147491599 DBW_DrvInptHiBeam 0 "Off" 1 "Auto" 2 "On" 3 "SNA" ;
VAL_ 2147491599 DBW_DrvInptTurnSignal 0 "Off" 1 "Left" 2 "Right" 3 "SNA" ;
VAL_ 2147491599 DBW_DrvInptWiper 0 "Off" 1 "Wiper_Intermittent1" 2 "Wiper_Intermittent2" 3 "Wiper_Intermittent3" 4 "Wiper_Intermittent4" 5 "Wiper_Intermittent5" 6 "Wiper_Intermittent6" 11 "Wiper_ConstantLowSpd" 12 "Wiper_ConstantHighSpd" 13 "Wiper_WashBrief" 14 "Wiper_WashContinuous" 15 "SNA" ;
VAL_ 2147491600 DBW_SonarArcNumRR 15 "No ARC" 8 "ARC8" 7 "ARC7" 6 "ARC6" 5 "ARC5" 4 "ARC4" 3 "ARC3" 2 "ARC2" 1 "ARC1" 0 "NODist" ;
VAL_ 2147491600 DBW_SonarArcNumRL 15 "No ARC" 8 "ARC8" 7 "ARC7" 6 "ARC6" 5 "ARC5" 4 "ARC4" 3 "ARC3" 2 "ARC2" 1 "ARC1" 0 "NODist" ;
VAL_ 2147491600 DBW_SonarArcNumRC 15 "No ARC" 8 "ARC8" 7 "ARC7" 6 "ARC6" 5 "ARC5" 4 "ARC4" 3 "ARC3" 2 "ARC2" 1 "ARC1" 0 "NODist" ;
VAL_ 2147491600 DBW_SonarArcNumFR 15 "No ARC" 8 "ARC8" 7 "ARC7" 6 "ARC6" 5 "ARC5" 4 "ARC4" 3 "ARC3" 2 "ARC2" 1 "ARC1" 0 "NODist" ;
VAL_ 2147491600 DBW_SonarArcNumFL 15 "No ARC" 8 "ARC8" 7 "ARC7" 6 "ARC6" 5 "ARC5" 4 "ARC4" 3 "ARC3" 2 "ARC2" 1 "ARC1" 0 "NODist" ;
VAL_ 2147491600 DBW_SonarArcNumFC 15 "No ARC" 8 "ARC8" 7 "ARC7" 6 "ARC6" 5 "ARC5" 4 "ARC4" 3 "ARC3" 2 "ARC2" 1 "ARC1" 0 "NODist" ;
VAL_ 1807 FltTxt_FaultStatus 1 "Occurred" 2 "Active" ;
VAL_ 2147491604 DBW_TurnSignalState 0 "Off" 1 "Left" 2 "Right" 3 "Hazards" 7 "SNA (Fault or Not Supported)" ;
VAL_ 2147491604 DBW_RightRearDoorState 0 "Undefined" 1 "Closed" 2 "Open" 3 "SNA (Faulted or Not Supported)" ;
VAL_ 2147491604 DBW_HighBeamState 0 "Undefined/Off" 2 "On" 1 "Auto" 3 "SNA (Faulted or Not Supported)" ;
VAL_ 2147491604 DBW_FrontWiperState 0 "Off" 1 "Wiper_Intermittent1" 2 "Wiper_Intermittent2" 3 "Wiper_Intermittent3" 4 "Wiper_Intermittent4" 5 "Wiper_Intermittent5" 6 "Wiper_Intermittent6" 11 "Wiper_ConstantLowSpd" 12 "Wiper_ConstantHighSpd" 13 "Wiper_WashBrief" 14 "Wiper_WashContinuous" 15 "SNA (Faulted or Not Supported)" ;
VAL_ 2147491604 DBW_RearWiperState 0 "Off" 1 "Wiper_Intermittent1" 11 "Wiper_ConstantLowSpd" 12 "Wiper_ConstantHighSpd" 13 "Wiper_WashBrief" 14 "Wiper_WashContinuous" 15 "SNA (Faulted or Not Supported)" ;
VAL_ 2147491604 DBW_IgnitionState 0 "Undefined" 1 "Off" 2 "Accessory" 3 "Run" 4 "Crank" 7 "SNA (Faulted or Not Supported)" ;
VAL_ 2147491604 DBW_LeftRearDoorState 0 "Undefined" 1 "Closed" 2 "Open" 3 "SNA (Faulted or Not Supported)" ;
VAL_ 2147491604 DBW_LiftgateDoorState 0 "Undefined" 1 "Closed" 2 "Open" 3 "SNA (Faulted or Not Supported)" ;
VAL_ 2147491604 DBW_HornState 0 "Off" 1 "On" 3 "SNA (Faulted or Not Supported)" ;
VAL_ 2147491604 DBW_LowBeamState 0 "Undefined/Off" 2 "On" 1 "Auto" 3 "SNA (Faulted or Not Supported)" ;
VAL_ 2147491604 DBW_RunningLightsState 0 "Undefined/Off" 2 "On" 1 "Auto" 3 "SNA (Faulted or Not Supported)" ;
VAL_ 2147491604 DBW_ModeLightState_Red 0 "Off" 1 "On" 3 "SNA" ;
VAL_ 2147491604 DBW_ModeLightState_Yellow 0 "Off" 1 "On" 3 "SNA" ;
VAL_ 2147491604 DBW_ModeLightState_Green 0 "Off" 1 "On" 3 "SNA" ;
VAL_ 2147491604 DBW_ModeLightState_Blue 0 "Off" 1 "On" 3 "SNA" ;
VAL_ 2147491604 DBW_DiffLockState 1 "On" 0 "Off" 3 "SNA" ;
VAL_ 2147491604 DBW_OtherLightsState 1 "On" 0 "Off" 3 "SNA" ;
VAL_ 2147491605 DBW_EmgrStopBtnPrssd 1 "Pressed" 0 "Not Pressed" ;
VAL_ 2147491605 DBW_RemoteEmgrStopBtnPrssd 0 "Not Pressed" 1 "Pressed" 3 "SNA" ;
VAL_ 2147495687 AKit_DumpBedReqType 0 "Mode" 1 "Angle" ;
VAL_ 2147495687 AKit_DumpBedModeReq 0 "Hold" 1 "Float" 2 "Lower" 3 "Raise" 4 "Auto Lower" 5 "Auto Raise" ;
VAL_ 2147495689 AKit_ArticulationReqType 1 "Angle" 0 "Flowrate" ;
VAL_ 2147495688 AKit_EngineModeReq 0 "No Request (Hold State)" 1 "Engine Off / Key Off" 3 "Engine On / Key On" 4 "Engine Force Off" 2 "Key On / Accessory" ;
VAL_ 2147491616 DBW_EngineKeyStateMismatch 0 "normal_op" 1 "keyOff_IgnOn" 2 "keyOn_IgnOff" ;
VAL_ 2147491616 DBW_EngineModeAct 0 "No Request (Hold State)" 2 "Key On / Accessory " 3 "Engine On / Key On" 4 "Engine Force Off" 1 "Engine Off / Key Off" ;
VAL_ 2147491616 DBW_EngineModeDes 0 "No Request (Hold State)" 2 "Key On / Accessory " 3 "Engine On / Key On" 4 "Engine Force Off" 1 "Engine Off / Key Off" ;
